VERSION "dbc-export 1 2026.26.6.5"

NS_ :

BS_:

BU_: APB APP APS DAS DPB EPAS3S EPASTS ESP GTW IBST IDB PARK RADC RCM RCM2 RCM3 RCU TPMS USM

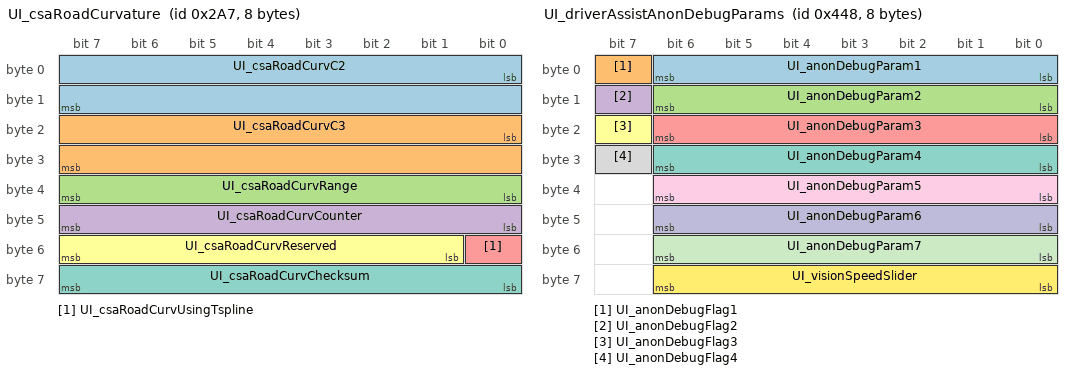
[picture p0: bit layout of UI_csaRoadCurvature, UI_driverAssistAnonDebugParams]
BO_ 679 UI_csaRoadCurvature: 8 GTW
 SG_ UI_csaRoadCurvC2 : 0|16@1- (1.0e-06,0) [-0.032768|0.032767] "1/m" Vector__XXX
 SG_ UI_csaRoadCurvC3 : 16|16@1- (4.0e-09,0) [-0.000131072|0.000131068] "1/m2" Vector__XXX
 SG_ UI_csaRoadCurvRange : 32|8@1+ (2,0) [0|510] "m" Vector__XXX
 SG_ UI_csaRoadCurvCounter : 40|8@1+ (1,0) [0|255] "" Vector__XXX
 SG_ UI_csaRoadCurvUsingTspline : 48|1@1+ (1,0) [0|1] "" Vector__XXX
 SG_ UI_csaRoadCurvReserved : 49|7@1+ (1,0) [0|127] "" Vector__XXX
 SG_ UI_csaRoadCurvChecksum : 56|8@1+ (1,0) [0|255] "" Vector__XXX

BO_ 1096 UI_driverAssistAnonDebugParams: 8 GTW
 SG_ UI_anonDebugParam1 : 0|7@1+ (1,0) [0|127] "" Vector__XXX
 SG_ UI_anonDebugFlag1 : 7|1@1+ (1,0) [0|1] "" Vector__XXX
 SG_ UI_anonDebugParam2 : 8|7@1+ (1,0) [0|127] "" Vector__XXX
 SG_ UI_anonDebugFlag2 : 15|1@1+ (1,0) [0|1] "" Vector__XXX
 SG_ UI_anonDebugParam3 : 16|7@1+ (1,0) [0|127] "" Vector__XXX
 SG_ UI_anonDebugFlag3 : 23|1@1+ (1,0) [0|1] "" Vector__XXX
 SG_ UI_anonDebugParam4 : 24|7@1+ (1,0) [0|127] "" Vector__XXX
 SG_ UI_anonDebugFlag4 : 31|1@1+ (1,0) [0|1] "" Vector__XXX
 SG_ UI_anonDebugParam5 : 32|7@1+ (1,0) [0|127] "" Vector__XXX
 SG_ UI_anonDebugParam6 : 40|7@1+ (1,0) [0|127] "" Vector__XXX
 SG_ UI_anonDebugParam7 : 48|7@1+ (1,0) [0|127] "" Vector__XXX
 SG_ UI_visionSpeedSlider : 56|7@1+ (1,0) [0|127] "" Vector__XXX

BO_ 1016 UI_driverAssistControl: 8 GTW
 SG_ UI_autopilotControlRequest : 0|1@1+ (1,0) [0|1] "" Vector__XXX
 SG_ UI_ulcStalkConfirm : 1|1@1+ (1,0) [0|1] "" Vector__XXX
 SG_ UI_summonHeartbeat : 2|2@1+ (1,0) [0|3] "" Vector__XXX
 SG_ UI_curvSpeedAdaptDisable : 4|1@1+ (1,0) [0|1] "" Vector__XXX
 SG_ UI_dasDeveloper : 5|1@1+ (1,0) [0|1] "" Vector__XXX
 SG_ UI_enableVinAssociation : 6|1@1+ (1,0) [0|1] "" Vector__XXX
 SG_ UI_lssLkaEnabled : 7|1@1+ (1,0) [0|1] "" Vector__XXX
 SG_ UI_lssLdwEnabled : 8|1@1+ (1,0) [0|1] "" Vector__XXX
 SG_ UI_coastToCoast : 9|1@1+ (1,0) [0|1] "" Vector__XXX
 SG_ UI_autoSummonEnable : 10|1@1+ (1,0) [0|1] "" Vector__XXX
 SG_ UI_exceptionListEnable : 11|1@1+ (1,0) [0|1] "" Vector__XXX
 SG_ UI_roadCheckDisable : 12|1@1+ (1,0) [0|1] "" Vector__XXX
 SG_ UI_driveOnMapsEnable : 13|1@1+ (1,0) [0|1] "" Vector__XXX
 SG_ UI_handsOnRequirementDisable : 14|1@1+ (1,0) [0|1] "" Vector__XXX
 SG_ UI_ulcOffHighway : 15|1@1+ (1,0) [0|1] "" Vector__XXX
 SG_ UI_fuseLanesDisable : 16|1@1+ (1,0) [0|1] "" Vector__XXX
 SG_ UI_fuseHPPDisable : 17|1@1+ (1,0) [0|1] "" Vector__XXX
 SG_ UI_fuseVehiclesDisable : 18|1@1+ (1,0) [0|1] "" Vector__XXX
 SG_ UI_enableClipParkedTelemetry : 19|1@1+ (1,0) [0|1] "" Vector__XXX
 SG_ UI_visionSpeedType : 20|2@1+ (1,0) [0|3] "" Vector__XXX
 SG_ UI_curvatureDatabaseOnly : 22|1@1+ (1,0) [0|1] "" Vector__XXX
 SG_ UI_lssElkEnabled : 23|1@1+ (1,0) [0|1] "" Vector__XXX
 SG_ UI_summonExitType : 24|2@1+ (1,0) [0|2] "" Vector__XXX
 SG_ UI_summonEntryType : 26|2@1+ (1,0) [0|2] "" Vector__XXX
 SG_ UI_selfParkRequest : 28|4@1+ (1,0) [0|14] "" Vector__XXX
 SG_ UI_summonReverseDist : 32|6@1+ (1,0) [0|62] "" Vector__XXX
 SG_ UI_undertakeAssistEnable : 38|1@1+ (1,0) [0|1] "" Vector__XXX
 SG_ UI_adaptiveSetSpeedEnable : 39|1@1+ (1,0) [0|1] "" Vector__XXX
 SG_ UI_drivingSide : 40|2@1+ (1,0) [0|3] "" Vector__XXX
 SG_ UI_enableClipTelemetry : 42|1@1+ (1,0) [0|1] "" Vector__XXX
 SG_ UI_enableTripTelemetry : 43|1@1+ (1,0) [0|1] "" Vector__XXX
 SG_ UI_enableRoadSegmentTelemetry : 44|1@1+ (1,0) [0|1] "" Vector__XXX
 SG_ UI_accFollowDistanceSetting : 45|3@1+ (1,0) [0|6] "" Vector__XXX
 SG_ UI_hasDriveOnNav : 48|1@1+ (1,0) [0|1] "" Vector__XXX
 SG_ UI_followNavRouteEnable : 49|1@1+ (1,0) [0|1] "" Vector__XXX
 SG_ UI_ulcSpeedConfig : 50|2@1+ (1,0) [0|3] "" Vector__XXX
 SG_ UI_ulcBlindSpotConfig : 52|2@1+ (1,0) [0|3] "" Vector__XXX
 SG_ UI_suppressExitPassingLane : 54|1@1+ (1,0) [0|1] "" Vector__XXX
 SG_ UI_enableClipStartStopTelemetry : 55|1@1+ (1,0) [0|1] "" Vector__XXX
 SG_ UI_alcOffHighwayEnable : 56|1@1+ (1,0) [0|1] "" Vector__XXX
 SG_ UI_validationLoop : 57|1@1+ (1,0) [0|1] "" Vector__XXX
 SG_ UI_smartSummonType : 58|2@1+ (1,0) [0|3] "" Vector__XXX
 SG_ UI_enableVisionOnlyStops : 60|1@1+ (1,0) [0|1] "" Vector__XXX
 SG_ UI_source3D : 61|2@1+ (1,0) [0|3] "" Vector__XXX
 SG_ UI_isaSpeedingChimeMuted : 63|1@1+ (1,0) [0|1] "" Vector__XXX

BO_ 568 UI_driverAssistMapData: 8 GTW
 SG_ UI_mapSpeedLimitDependency : 0|3@1+ (1,0) [0|6] "" Vector__XXX
 SG_ UI_roadClass : 3|3@1+ (1,0) [1|7] "" Vector__XXX
 SG_ UI_inSuperchargerGeofence : 6|1@1+ (1,0) [0|1] "" Vector__XXX
 SG_ UI_mapSpeedUnits : 7|1@1+ (1,0) [0|1] "" Vector__XXX
 SG_ UI_mapSpeedLimit : 8|5@1+ (1,0) [0|30] "" Vector__XXX
 SG_ UI_mapSpeedLimitType : 13|3@1+ (1,0) [0|6] "" Vector__XXX
 SG_ UI_countryCode : 16|10@1+ (1,0) [0|1022] "" Vector__XXX
 SG_ UI_streetCount : 26|2@1+ (1,0) [0|3] "" Vector__XXX
 SG_ UI_gpsRoadMatch : 28|1@1+ (1,0) [0|1] "" Vector__XXX
 SG_ UI_navRouteActive : 29|1@1+ (1,0) [0|1] "" Vector__XXX
 SG_ UI_parallelAutoparkEnabled : 30|1@1+ (1,0) [0|1] "" Vector__XXX
 SG_ UI_perpendicularAutoparkEnabled : 31|1@1+ (1,0) [0|1] "" Vector__XXX
 SG_ UI_nextBranchDist : 32|5@1+ (10,0) [0|300] "m" Vector__XXX
 SG_ UI_controlledAccess : 37|1@1+ (1,0) [0|1] "" Vector__XXX
 SG_ UI_nextBranchLeftOffRamp : 38|1@1+ (1,0) [0|1] "" Vector__XXX
 SG_ UI_nextBranchRightOffRamp : 39|1@1+ (1,0) [0|1] "" Vector__XXX
 SG_ UI_rejectLeftLane : 40|1@1+ (1,0) [0|1] "" Vector__XXX
 SG_ UI_rejectRightLane : 41|1@1+ (1,0) [0|1] "" Vector__XXX
 SG_ UI_rejectHPP : 42|1@1+ (1,0) [0|1] "" Vector__XXX
 SG_ UI_rejectNav : 43|1@1+ (1,0) [0|1] "" Vector__XXX
 SG_ UI_rejectLeftFreeSpace : 44|1@1+ (1,0) [0|1] "" Vector__XXX
 SG_ UI_rejectRightFreeSpace : 45|1@1+ (1,0) [0|1] "" Vector__XXX
 SG_ UI_rejectAutosteer : 46|1@1+ (1,0) [0|1] "" Vector__XXX
 SG_ UI_rejectHandsOn : 47|1@1+ (1,0) [0|1] "" Vector__XXX
 SG_ UI_acceptBottsDots : 48|1@1+ (1,0) [0|1] "" Vector__XXX
 SG_ UI_autosteerRestricted : 49|1@1+ (1,0) [0|1] "" Vector__XXX
 SG_ UI_pmmEnabled : 50|1@1+ (1,0) [0|1] "" Vector__XXX
 SG_ UI_scaEnabled : 51|1@1+ (1,0) [0|1] "" Vector__XXX
 SG_ UI_mapDataCounter : 52|4@1+ (1,0) [0|15] "" Vector__XXX
 SG_ UI_mapDataChecksum : 56|8@1+ (1,0) [0|255] "" Vector__XXX

BO_ 536 UI_driverAssistRoadSign: 8 GTW
 SG_ UI_roadSign M : 0|8@1+ (1,0) [0|254] "" Vector__XXX
 SG_ UI_splineLocConfidence : 40|7@1+ (1,0) [1|127] "1" Vector__XXX
 SG_ UI_splineID : 48|4@1+ (1,0) [0|15] "" Vector__XXX
 SG_ UI_roadSignCounter : 52|4@1+ (1,0) [0|15] "" Vector__XXX
 SG_ UI_roadSignChecksum : 56|8@1+ (1,0) [0|255] "" Vector__XXX
 SG_ UI_dummyData m0 : 8|1@1+ (1,0) [0|1] "" Vector__XXX
 SG_ UI_stopSignStopLineDist m1 : 8|10@1+ (0.25,-8) [-8|247.5] "m" Vector__XXX
 SG_ UI_stopSignStopLineConf m1 : 18|7@1+ (1,0) [1|127] "1" Vector__XXX
 SG_ UI_trafficLightStopLineDist m2 : 8|10@1+ (0.25,-8) [-8|247.5] "m" Vector__XXX
 SG_ UI_trafficLightStopLineConf m2 : 18|7@1+ (1,0) [1|127] "1" Vector__XXX
 SG_ UI_baseMapSpeedLimitMPS m3 : 8|8@1+ (0.25,0) [0|63.5] "m/s" Vector__XXX
 SG_ UI_bottomQrtlFleetSpeedMPS m3 : 16|8@1+ (0.25,0) [0|63.5] "m/s" Vector__XXX
 SG_ UI_topQrtlFleetSpeedMPS m3 : 24|8@1+ (0.25,0) [0|63.5] "m/s" Vector__XXX
 SG_ UI_meanFleetSplineSpeedMPS m4 : 8|8@1+ (0.25,0) [0|63.5] "m/s" Vector__XXX
 SG_ UI_medianFleetSpeedMPS m4 : 16|8@1+ (0.25,0) [0|63.5] "m/s" Vector__XXX
 SG_ UI_meanFleetSplineAccelMPS2 m4 : 24|8@1+ (0.05,-6.35) [-6.35|6.35] "m/s^2" Vector__XXX
 SG_ UI_rampType m4 : 32|3@1+ (1,0) [1|7] "" Vector__XXX
 SG_ UI_valhallaRamp m4 : 35|2@1+ (1,0) [1|3] "" Vector__XXX
 SG_ UI_overrideACMFleetSpeed m4 : 38|1@1+ (1,0) [0|1] "" Vector__XXX
 SG_ UI_currSplineIdFull m5 : 8|32@1+ (1,0) [1|4294967295] "1" Vector__XXX

BO_ 1971 UI_dynamicTriggersCampaignFired: 8 GTW
 SG_ UI_campaignFired : 0|64@1+ (1,0) [0|1.84467440737e+19] "" Vector__XXX

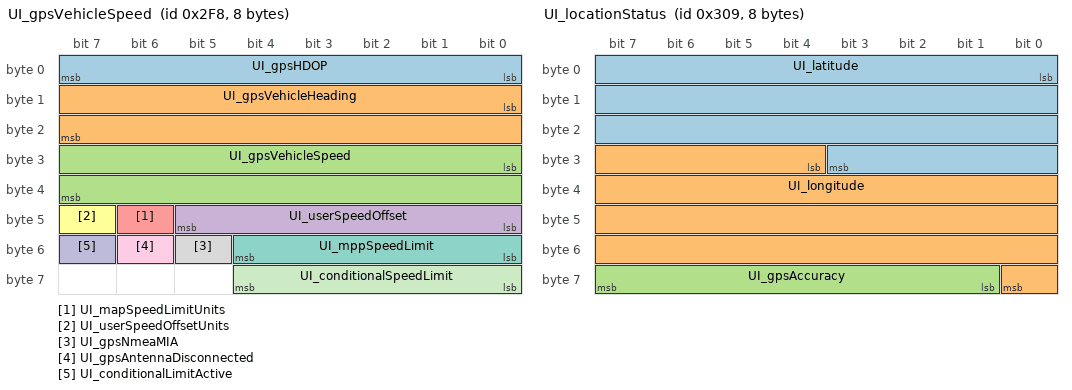
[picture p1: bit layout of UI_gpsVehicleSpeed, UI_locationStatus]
BO_ 760 UI_gpsVehicleSpeed: 8 GTW
 SG_ UI_gpsHDOP : 0|8@1+ (0.1,0) [0|25.5] "1" Vector__XXX
 SG_ UI_gpsVehicleHeading : 8|16@1+ (0.0078125,0) [0|511.9921875] "deg" Vector__XXX
 SG_ UI_gpsVehicleSpeed : 24|16@1+ (0.00390625,0) [0|255.99609375] "km/hr" Vector__XXX
 SG_ UI_userSpeedOffset : 40|6@1+ (1,-30) [-30|33] "kph/mph" Vector__XXX
 SG_ UI_mapSpeedLimitUnits : 46|1@1+ (1,0) [0|1] "" Vector__XXX
 SG_ UI_userSpeedOffsetUnits : 47|1@1+ (1,0) [0|1] "" Vector__XXX
 SG_ UI_mppSpeedLimit : 48|5@1+ (5,0) [0|155] "kph/mph" Vector__XXX
 SG_ UI_gpsNmeaMIA : 53|1@1+ (1,0) [0|1] "" Vector__XXX
 SG_ UI_gpsAntennaDisconnected : 54|1@1+ (1,0) [0|1] "" Vector__XXX
 SG_ UI_conditionalLimitActive : 55|1@1+ (1,0) [0|1] "" Vector__XXX
 SG_ UI_conditionalSpeedLimit : 56|5@1+ (5,0) [0|150] "kph/mph" Vector__XXX

BO_ 985 UI_locationOffset: 8 GTW
 SG_ UI_latitudeOffset : 0|28@1- (1.0e-06,0) [-134.217728|134.217727] "deg" Vector__XXX
 SG_ UI_longitudeOffset : 28|29@1- (1.0e-06,0) [-268.435456|268.435455] "deg" Vector__XXX

BO_ 777 UI_locationStatus: 8 GTW
 SG_ UI_latitude : 0|28@1- (1.0e-06,0) [-134.217728|134.217727] "deg" Vector__XXX
 SG_ UI_longitude : 28|29@1- (1.0e-06,0) [-268.435456|268.435455] "deg" Vector__XXX
 SG_ UI_gpsAccuracy : 57|7@1+ (0.2,0) [0|25.2] "m" Vector__XXX

BO_ 1011 UI_odo: 3 GTW
 SG_ UI_odometer : 0|24@1+ (0.1,0) [0|1677721.4] "km" Vector__XXX

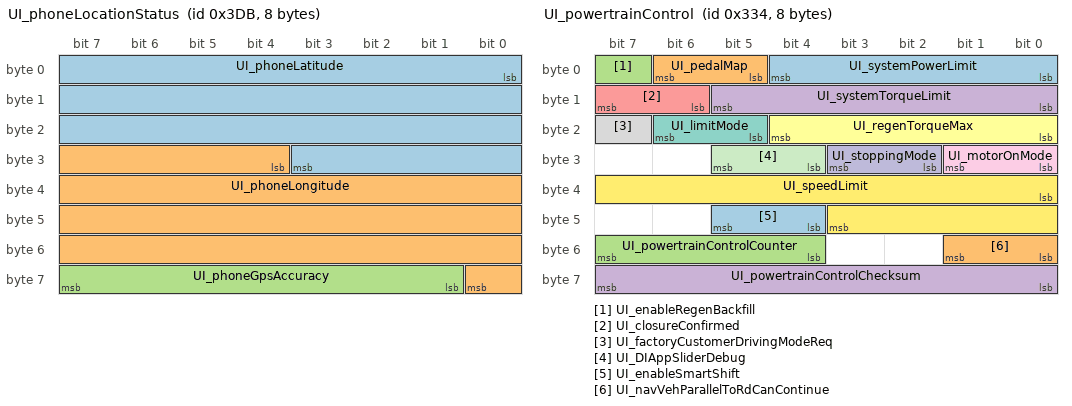
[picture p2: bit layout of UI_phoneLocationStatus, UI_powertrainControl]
BO_ 987 UI_phoneLocationStatus: 8 GTW
 SG_ UI_phoneLatitude : 0|28@1- (1.0e-06,0) [-134.217728|134.217727] "deg" Vector__XXX
 SG_ UI_phoneLongitude : 28|29@1- (1.0e-06,0) [-268.435456|268.435455] "deg" Vector__XXX
 SG_ UI_phoneGpsAccuracy : 57|7@1+ (0.5,0) [0|63] "m" Vector__XXX

BO_ 820 UI_powertrainControl: 8 GTW
 SG_ UI_systemPowerLimit : 0|5@1+ (20,20) [20|620] "kW" Vector__XXX
 SG_ UI_pedalMap : 5|2@1+ (1,0) [0|3] "" Vector__XXX
 SG_ UI_enableRegenBackfill : 7|1@1+ (1,0) [0|1] "" Vector__XXX
 SG_ UI_systemTorqueLimit : 8|6@1+ (150,1000) [1000|10300] "Nm" Vector__XXX
 SG_ UI_closureConfirmed : 14|2@1+ (1,0) [0|3] "" Vector__XXX
 SG_ UI_regenTorqueMax : 16|5@1+ (5,0) [0|100] "%" Vector__XXX
 SG_ UI_limitMode : 21|2@1+ (1,0) [0|3] "" Vector__XXX
 SG_ UI_factoryCustomerDrivingModeReq : 23|1@1+ (1,0) [0|1] "" Vector__XXX
 SG_ UI_motorOnMode : 24|2@1+ (1,0) [0|3] "" Vector__XXX
 SG_ UI_stoppingMode : 26|2@1+ (1,0) [0|3] "" Vector__XXX
 SG_ UI_DIAppSliderDebug : 28|2@1+ (1,0) [0|3] "" Vector__XXX
 SG_ UI_speedLimit : 32|12@1+ (0.1,0) [0|335] "kph" Vector__XXX
 SG_ UI_enableSmartShift : 44|2@1+ (1,0) [0|3] "" Vector__XXX
 SG_ UI_navVehParallelToRdCanContinue : 48|2@1+ (1,0) [1|3] "" Vector__XXX
 SG_ UI_powertrainControlCounter : 52|4@1+ (1,0) [0|15] "" Vector__XXX
 SG_ UI_powertrainControlChecksum : 56|8@1+ (1,0) [0|255] "" Vector__XXX

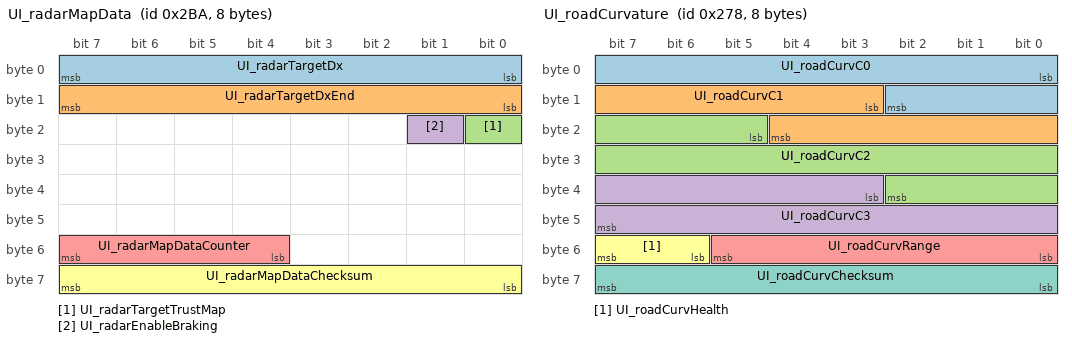
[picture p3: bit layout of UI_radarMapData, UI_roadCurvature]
BO_ 698 UI_radarMapData: 8 GTW
 SG_ UI_radarTargetDx : 0|8@1+ (1,-95) [-95|160] "m" Vector__XXX
 SG_ UI_radarTargetDxEnd : 8|8@1+ (1,0) [0|255] "m" Vector__XXX
 SG_ UI_radarTargetTrustMap : 16|1@1+ (1,0) [0|1] "" Vector__XXX
 SG_ UI_radarEnableBraking : 17|1@1+ (1,0) [0|1] "" Vector__XXX
 SG_ UI_radarMapDataCounter : 52|4@1+ (1,0) [0|15] "" Vector__XXX
 SG_ UI_radarMapDataChecksum : 56|8@1+ (1,0) [0|255] "" Vector__XXX

BO_ 632 UI_roadCurvature: 8 GTW
 SG_ UI_roadCurvC0 : 0|11@1- (0.02,0) [-20.48|20.46] "m" Vector__XXX
 SG_ UI_roadCurvC1 : 11|10@1- (0.00075,0) [-0.384|0.38325] "1" Vector__XXX
 SG_ UI_roadCurvC2 : 21|14@1- (7.5e-06,0) [-0.06144|0.0614325] "1/m" Vector__XXX
 SG_ UI_roadCurvC3 : 35|13@1- (3.0e-08,0) [-0.00012288|0.00012285] "1/m2" Vector__XXX
 SG_ UI_roadCurvRange : 48|6@1+ (4,0) [0|252] "m" Vector__XXX
 SG_ UI_roadCurvHealth : 54|2@1+ (1,0) [0|3] "" Vector__XXX
 SG_ UI_roadCurvChecksum : 56|8@1+ (1,0) [0|255] "" Vector__XXX

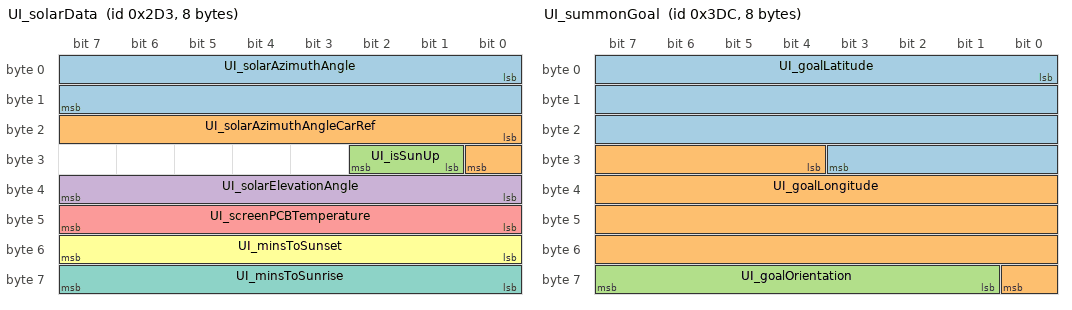
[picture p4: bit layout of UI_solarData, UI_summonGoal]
BO_ 723 UI_solarData: 8 GTW
 SG_ UI_solarAzimuthAngle : 0|16@1- (1,0) [-32768|32767] "degrees" Vector__XXX
 SG_ UI_solarAzimuthAngleCarRef : 16|9@1- (1,0) [-256|254] "degrees" Vector__XXX
 SG_ UI_isSunUp : 25|2@1+ (1,0) [0|2] "" Vector__XXX
 SG_ UI_solarElevationAngle : 32|8@1- (1,0) [-128|126] "degrees" Vector__XXX
 SG_ UI_screenPCBTemperature : 40|8@1- (0.5,40) [-20|100] "degC" Vector__XXX
 SG_ UI_minsToSunset : 48|8@1+ (10,0) [0|2550] "min" Vector__XXX
 SG_ UI_minsToSunrise : 56|8@1+ (10,0) [0|2550] "min" Vector__XXX

BO_ 851 UI_status: 8 GTW
 SG_ UI_touchActive : 0|1@1+ (1,0) [0|1] "" Vector__XXX
 SG_ UI_audioActive : 1|1@1+ (1,0) [0|1] "" Vector__XXX
 SG_ UI_bluetoothActive : 2|1@1+ (1,0) [0|1] "" Vector__XXX
 SG_ UI_cellActive : 3|1@1+ (1,0) [0|1] "" Vector__XXX
 SG_ UI_displayReady : 4|1@1+ (1,0) [0|1] "" Vector__XXX
 SG_ UI_displayOn : 5|1@1+ (1,0) [0|1] "" Vector__XXX
 SG_ UI_wifiActive : 6|1@1+ (1,0) [0|1] "" Vector__XXX
 SG_ UI_wifiConnected : 7|1@1+ (1,0) [0|1] "" Vector__XXX
 SG_ UI_systemActive : 8|1@1+ (1,0) [0|1] "" Vector__XXX
 SG_ UI_readyForDrive : 9|1@1+ (1,0) [0|1] "" Vector__XXX
 SG_ UI_cellConnected : 10|1@1+ (1,0) [0|1] "" Vector__XXX
 SG_ UI_vpnActive : 11|1@1+ (1,0) [0|1] "" Vector__XXX
 SG_ UI_autopilotTrial : 12|2@1+ (1,0) [0|3] "" Vector__XXX
 SG_ UI_factoryReset : 14|2@1+ (1,0) [1|3] "" Vector__XXX
 SG_ UI_gpsActive : 16|1@1+ (1,0) [0|1] "" Vector__XXX
 SG_ UI_screenshotActive : 17|1@1+ (1,0) [0|1] "" Vector__XXX
 SG_ UI_radioActive : 18|1@1+ (1,0) [0|1] "" Vector__XXX
 SG_ UI_cellNetworkTechnology : 19|4@1+ (1,0) [0|14] "" Vector__XXX
 SG_ UI_cellReceiverPower : 24|8@1+ (1,-128) [-128|127] "dB" Vector__XXX
 SG_ UI_falseTouchCounter : 32|8@1+ (1,0) [0|255] "1" Vector__XXX
 SG_ UI_developmentCar : 40|1@1+ (1,0) [0|1] "" Vector__XXX
 SG_ UI_cameraActive : 41|1@1+ (1,0) [0|1] "" Vector__XXX
 SG_ UI_cellSignalBars : 42|3@1+ (1,0) [0|6] "" Vector__XXX
 SG_ UI_trailerModeTelltale : 45|2@1+ (1,0) [0|3] "" Vector__XXX
 SG_ UI_pcbTemperature : 48|8@1- (1,40) [-20|100] "degC" Vector__XXX
 SG_ UI_cpuTemperature : 56|8@1- (1,40) [-20|100] "degC" Vector__XXX

BO_ 991 UI_status2: 8 GTW
 SG_ UI_mobileAppStepCount : 0|16@1+ (1,0) [0|65535] "" Vector__XXX
 SG_ UI_userRequestSnapshot : 16|1@1+ (1,0) [0|1] "" Vector__XXX
 SG_ UI_touchDetected : 17|1@1+ (1,0) [0|1] "" Vector__XXX
 SG_ UI_validDeviceForEUSummon : 18|1@1+ (1,0) [0|1] "" Vector__XXX
 SG_ UI_locatedAtHome : 19|1@1+ (1,0) [0|1] "" Vector__XXX
 SG_ UI_locatedAtWork : 20|1@1+ (1,0) [0|1] "" Vector__XXX
 SG_ UI_locatedAtFavorite : 21|1@1+ (1,0) [0|1] "" Vector__XXX
 SG_ UI_displayInDarkMode : 22|1@1+ (1,0) [0|1] "" Vector__XXX
 SG_ UI_userActivity : 23|1@1+ (1,0) [0|1] "" Vector__XXX
 SG_ UI_activeTouchPoints : 24|8@1+ (1,0) [0|255] "1" Vector__XXX
 SG_ UI_linkState : 32|2@1+ (1,0) [0|3] "" Vector__XXX
 SG_ UI_sentryModeState : 34|3@1+ (1,0) [0|7] "" Vector__XXX
 SG_ UI_autopilotSentryRequest : 37|1@1+ (1,0) [0|1] "" Vector__XXX
 SG_ UI_mobileAppConnected : 38|1@1+ (1,0) [0|1] "" Vector__XXX
 SG_ UI_phoneLeftInCabin : 39|1@1+ (1,0) [0|1] "" Vector__XXX
 SG_ UI_autoshiftDRState : 40|3@1+ (1,0) [0|7] "" Vector__XXX
 SG_ UI_wifiBtModuleType : 43|3@1+ (1,0) [0|7] "" Vector__XXX
 SG_ UI_sohHealthStatus : 46|2@1+ (1,0) [0|3] "" Vector__XXX
 SG_ UI_selfParkState : 48|8@1+ (1,0) [0|254] "" Vector__XXX
 SG_ UI_summonDeviceIndex : 56|2@1+ (1,0) [0|3] "" Vector__XXX
 SG_ UI_fullScreenMode : 58|1@1+ (1,0) [0|1] "" Vector__XXX
 SG_ UI_sentryModeCameraDetection : 59|1@1+ (1,0) [0|1] "" Vector__XXX
 SG_ UI_wakeOnIPActive : 60|1@1+ (1,0) [0|1] "" Vector__XXX
 SG_ UI_sapActive : 61|1@1+ (1,0) [0|1] "" Vector__XXX
 SG_ UI_sapClients : 62|1@1+ (1,0) [0|1] "" Vector__XXX
 SG_ UI_connectivityStandbyActive : 63|1@1+ (1,0) [0|1] "" Vector__XXX

BO_ 988 UI_summonGoal: 8 GTW
 SG_ UI_goalLatitude : 0|28@1- (1.0e-06,0) [-134.217728|134.217727] "deg" Vector__XXX
 SG_ UI_goalLongitude : 28|29@1- (1.0e-06,0) [-268.435456|268.435455] "deg" Vector__XXX
 SG_ UI_goalOrientation : 57|7@1+ (2.8125,0) [0|357.1875] "deg" Vector__XXX

BO_ 1064 UI_telemetryControl: 8 GTW
 SG_ UI_TCR_enable : 0|1@1+ (1,0) [0|1] "" Vector__XXX
 SG_ UI_TCR_moveStateStanding : 1|1@1+ (1,0) [0|1] "" Vector__XXX
 SG_ UI_TCR_moveStateStopped : 2|1@1+ (1,0) [0|1] "" Vector__XXX
 SG_ UI_TCR_moveStateMoving : 3|1@1+ (1,0) [0|1] "" Vector__XXX
 SG_ UI_TCR_moveStateIndeterm : 4|1@1+ (1,0) [0|1] "" Vector__XXX
 SG_ UI_TCR_classConstElem : 5|1@1+ (1,0) [0|1] "" Vector__XXX
 SG_ UI_TCR_classMovingPed : 6|1@1+ (1,0) [0|1] "" Vector__XXX
 SG_ UI_TCR_classMovingTwoWheel : 7|1@1+ (1,0) [0|1] "" Vector__XXX
 SG_ UI_TCR_classMovingFourWheel : 8|1@1+ (1,0) [0|1] "" Vector__XXX
 SG_ UI_TCR_classUnknown : 9|1@1+ (1,0) [0|1] "" Vector__XXX
 SG_ UI_TCR_downSampleFactor : 10|4@1+ (1,0) [0|15] "" Vector__XXX
 SG_ UI_TCR_wExist : 24|5@1+ (1,0) [0|31] "" Vector__XXX
 SG_ UI_TCR_vehSpeed : 32|8@1+ (1,0) [0|255] "" Vector__XXX
 SG_ UI_TCR_minRCS : 40|8@1+ (0.25,-14) [-14|49.75] "dB" Vector__XXX
 SG_ UI_TCR_maxDy : 48|5@1+ (0.5,0) [0|15.5] "m" Vector__XXX
 SG_ UI_TCR_maxObjects : 56|5@1+ (1,0) [0|31] "" Vector__XXX
 SG_ UI_TCR_maxRoadClass : 61|3@1+ (1,0) [0|7] "" Vector__XXX

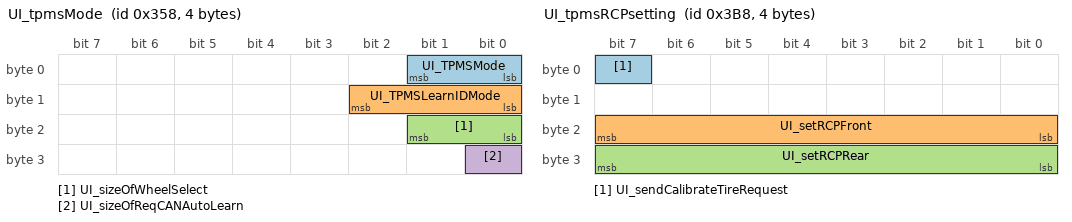
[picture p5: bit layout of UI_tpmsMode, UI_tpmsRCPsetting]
BO_ 856 UI_tpmsMode: 4 GTW
 SG_ UI_TPMSMode : 0|2@1+ (1,0) [0|3] "" Vector__XXX
 SG_ UI_TPMSLearnIDMode : 8|3@1+ (1,0) [0|7] "" Vector__XXX
 SG_ UI_sizeOfWheelSelect : 16|2@1+ (1,0) [0|3] "" Vector__XXX
 SG_ UI_sizeOfReqCANAutoLearn : 24|1@1+ (1,0) [0|1] "" Vector__XXX

BO_ 952 UI_tpmsRCPsetting: 4 GTW
 SG_ UI_sendCalibrateTireRequest : 7|1@1+ (1,0) [0|1] "" Vector__XXX
 SG_ UI_setRCPFront : 16|8@1+ (0.025,0) [0|6.375] "bar" Vector__XXX
 SG_ UI_setRCPRear : 24|8@1+ (0.025,0) [0|6.375] "bar" Vector__XXX

BO_ 852 UI_uiHealthStatus: 6 GTW
 SG_ UI_centerDisplayRunning : 0|1@1+ (1,0) [0|1] "" Vector__XXX
 SG_ UI_centerDisplaySM : 1|3@1+ (1,0) [0|7] "" Vector__XXX
 SG_ UI_centerDisplayPowerOn : 4|1@1+ (1,0) [0|1] "" Vector__XXX
 SG_ UI_centerDisplayCrtcOk : 5|1@1+ (1,0) [0|1] "" Vector__XXX
 SG_ UI_centerDisplayHardwareOk : 6|1@1+ (1,0) [0|1] "" Vector__XXX
 SG_ UI_centerDisplayWindowManagerOk : 7|1@1+ (1,0) [0|1] "" Vector__XXX
 SG_ UI_centerDisplayCompositorOk : 8|1@1+ (1,0) [0|1] "" Vector__XXX
 SG_ UI_apVisualizationOk : 9|1@1+ (1,0) [0|1] "" Vector__XXX
 SG_ UI_autonomyCenterDispStatus : 10|2@1+ (1,0) [1|3] "" Vector__XXX
 SG_ UI_autonomyRearDispStatus : 12|2@1+ (1,0) [1|3] "" Vector__XXX
 SG_ UI_autonomyConnectivityStatus : 14|2@1+ (1,0) [1|3] "" Vector__XXX
 SG_ UI_autonomyConnectivtyHWOk : 16|1@1+ (1,0) [0|1] "" Vector__XXX
 SG_ UI_autonomyQtCarStatus : 17|2@1+ (1,0) [1|3] "" Vector__XXX
 SG_ UI_autonomyQtCarRearStatus : 19|2@1+ (1,0) [1|3] "" Vector__XXX
 SG_ UI_autonomyDASServerStatus : 21|2@1+ (1,0) [1|3] "" Vector__XXX
 SG_ UI_rearDisplayRunning : 23|1@1+ (1,0) [0|1] "" Vector__XXX
 SG_ UI_rearDisplayPowerOn : 24|1@1+ (1,0) [0|1] "" Vector__XXX
 SG_ UI_rearDisplaySM : 25|3@1+ (1,0) [0|7] "" Vector__XXX
 SG_ UI_rearDisplayCrtcOk : 28|1@1+ (1,0) [0|1] "" Vector__XXX
 SG_ UI_rearDisplayHardwareOk : 29|1@1+ (1,0) [0|1] "" Vector__XXX
 SG_ UI_rearDisplayWindowManagerOk : 30|1@1+ (1,0) [0|1] "" Vector__XXX
 SG_ UI_rearDisplayCompositorOk : 31|1@1+ (1,0) [0|1] "" Vector__XXX

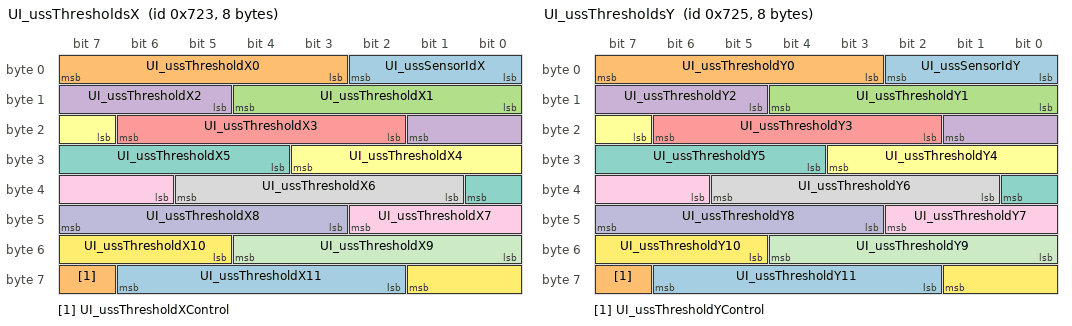
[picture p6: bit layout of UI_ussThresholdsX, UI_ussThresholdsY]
BO_ 1827 UI_ussThresholdsX: 8 GTW
 SG_ UI_ussSensorIdX : 0|3@1+ (1,0) [0|7] "" Vector__XXX
 SG_ UI_ussThresholdX0 : 3|5@1+ (1,0) [0|31] "" Vector__XXX
 SG_ UI_ussThresholdX1 : 8|5@1+ (1,0) [0|31] "" Vector__XXX
 SG_ UI_ussThresholdX2 : 13|5@1+ (1,0) [0|31] "" Vector__XXX
 SG_ UI_ussThresholdX3 : 18|5@1+ (1,0) [0|31] "" Vector__XXX
 SG_ UI_ussThresholdX4 : 23|5@1+ (1,0) [0|31] "" Vector__XXX
 SG_ UI_ussThresholdX5 : 28|5@1+ (1,0) [0|31] "" Vector__XXX
 SG_ UI_ussThresholdX6 : 33|5@1+ (1,0) [0|31] "" Vector__XXX
 SG_ UI_ussThresholdX7 : 38|5@1+ (1,0) [0|31] "" Vector__XXX
 SG_ UI_ussThresholdX8 : 43|5@1+ (1,0) [0|31] "" Vector__XXX
 SG_ UI_ussThresholdX9 : 48|5@1+ (1,0) [0|31] "" Vector__XXX
 SG_ UI_ussThresholdX10 : 53|5@1+ (1,0) [0|31] "" Vector__XXX
 SG_ UI_ussThresholdX11 : 58|5@1+ (1,0) [0|31] "" Vector__XXX
 SG_ UI_ussThresholdXControl : 63|1@1+ (1,0) [0|1] "" Vector__XXX

BO_ 1829 UI_ussThresholdsY: 8 GTW
 SG_ UI_ussSensorIdY : 0|3@1+ (1,0) [0|7] "" Vector__XXX
 SG_ UI_ussThresholdY0 : 3|5@1+ (1,0) [0|31] "" Vector__XXX
 SG_ UI_ussThresholdY1 : 8|5@1+ (1,0) [0|31] "" Vector__XXX
 SG_ UI_ussThresholdY2 : 13|5@1+ (1,0) [0|31] "" Vector__XXX
 SG_ UI_ussThresholdY3 : 18|5@1+ (1,0) [0|31] "" Vector__XXX
 SG_ UI_ussThresholdY4 : 23|5@1+ (1,0) [0|31] "" Vector__XXX
 SG_ UI_ussThresholdY5 : 28|5@1+ (1,0) [0|31] "" Vector__XXX
 SG_ UI_ussThresholdY6 : 33|5@1+ (1,0) [0|31] "" Vector__XXX
 SG_ UI_ussThresholdY7 : 38|5@1+ (1,0) [0|31] "" Vector__XXX
 SG_ UI_ussThresholdY8 : 43|5@1+ (1,0) [0|31] "" Vector__XXX
 SG_ UI_ussThresholdY9 : 48|5@1+ (1,0) [0|31] "" Vector__XXX
 SG_ UI_ussThresholdY10 : 53|5@1+ (1,0) [0|31] "" Vector__XXX
 SG_ UI_ussThresholdY11 : 58|5@1+ (1,0) [0|31] "" Vector__XXX
 SG_ UI_ussThresholdYControl : 63|1@1+ (1,0) [0|1] "" Vector__XXX

BO_ 947 UI_vehicleControl2: 8 GTW
 SG_ UI_gloveboxRequest : 0|1@1+ (1,0) [0|1] "" Vector__XXX
 SG_ UI_trunkRequest : 1|1@1+ (1,0) [0|1] "" Vector__XXX
 SG_ UI_UMCUpdateInhibit : 2|1@1+ (1,0) [0|1] "" Vector__XXX
 SG_ UI_WCUpdateInhibit : 3|1@1+ (1,0) [0|1] "" Vector__XXX
 SG_ UI_soundHornOnLock : 4|1@1+ (1,0) [0|1] "" Vector__XXX
 SG_ UI_locksPanelActive : 5|1@1+ (1,0) [0|1] "" Vector__XXX
 SG_ UI_PINToDriveEnabled : 6|1@1+ (1,0) [0|1] "" Vector__XXX
 SG_ UI_PINToDrivePassed : 7|1@1+ (1,0) [0|1] "" Vector__XXX
 SG_ UI_disableMirrorAutoDim : 8|1@1+ (1,0) [0|1] "" Vector__XXX
 SG_ UI_lightSwitch : 9|3@1+ (1,0) [0|7] "" Vector__XXX
 SG_ UI_readyToAddKey : 12|1@1+ (1,0) [0|1] "" Vector__XXX
 SG_ UI_alarmTriggerRequest : 13|1@1+ (1,0) [0|1] "" Vector__XXX
 SG_ UI_VCSECFeature1 : 14|1@1+ (1,0) [0|1] "" Vector__XXX
 SG_ UI_VCLEFTFeature1 : 15|1@1+ (1,0) [0|1] "" Vector__XXX
 SG_ UI_summonState : 16|2@1+ (1,0) [1|3] "" Vector__XXX
 SG_ UI_displayOnForUser : 18|1@1+ (1,0) [0|1] "" Vector__XXX
 SG_ UI_freeRollModeRequest : 19|1@1+ (1,0) [0|1] "" Vector__XXX
 SG_ UI_BLEPushNotificationRequest : 20|1@1+ (1,0) [0|1] "" Vector__XXX
 SG_ UI_pairKeyQRCodeDisplaying : 21|1@1+ (1,0) [0|1] "" Vector__XXX
 SG_ UI_keepAutopilotAwake : 22|1@1+ (1,0) [0|1] "" Vector__XXX
 SG_ UI_batteryPreconditioningRequest : 23|1@1+ (1,0) [0|1] "" Vector__XXX
 SG_ UI_coastDownMode : 24|1@1+ (1,0) [0|1] "" Vector__XXX
 SG_ UI_autopilotPowerStateRequest : 25|2@1+ (1,0) [0|3] "" Vector__XXX
 SG_ UI_shorted12VCellTestMode : 27|2@1+ (1,0) [0|3] "" Vector__XXX
 SG_ UI_autoRollWindowsOnLockEnable : 29|1@1+ (1,0) [0|1] "" Vector__XXX
 SG_ UI_virtualPitchSensorOverrideOKF : 30|1@1+ (1,0) [0|1] "" Vector__XXX
 SG_ UI_conditionalLoggingEnabledVCSE : 31|1@1+ (1,0) [0|1] "" Vector__XXX
 SG_ UI_WC3UpdateInhibit : 32|1@1+ (1,0) [0|1] "" Vector__XXX
 SG_ UI_steeringWheelHeatReq : 33|1@1+ (1,0) [0|1] "" Vector__XXX
 SG_ UI_disableHorn : 34|1@1+ (1,0) [0|1] "" Vector__XXX
 SG_ UI_frontLeftSeatFanReq : 37|2@1+ (1,0) [0|3] "" Vector__XXX
 SG_ UI_frontRightSeatAutoClimateReq : 39|1@1+ (1,0) [0|1] "" Vector__XXX
 SG_ UI_frontRightSeatFanReq : 40|2@1+ (1,0) [0|3] "" Vector__XXX
 SG_ UI_3RLeftSeatHeatReq : 44|2@1+ (1,0) [0|3] "" Vector__XXX
 SG_ UI_3RRightSeatHeatReq : 46|2@1+ (1,0) [0|3] "" Vector__XXX
 SG_ UI_sleepFeature1 : 51|1@1+ (1,0) [0|1] "" Vector__XXX
 SG_ UI_dcr12VThreshold : 52|4@1+ (1,0) [0|15] "" Vector__XXX
 SG_ UI_frontLeftSeatAutoClimateReq : 56|1@1+ (1,0) [0|1] "" Vector__XXX
 SG_ UI_wiperHeaterReq : 57|1@1+ (1,0) [0|1] "" Vector__XXX
 SG_ UI_tireSeason : 59|1@1+ (1,0) [0|1] "" Vector__XXX
 SG_ UI_saveTireConfigReq : 60|1@1+ (1,0) [0|1] "" Vector__XXX
 SG_ UI_silentAlarm : 61|1@1+ (1,0) [0|1] "" Vector__XXX
 SG_ UI_sleepFeature2 : 63|1@1+ (1,0) [0|1] "" Vector__XXX

BO_ 644 UI_vehicleModes: 8 GTW
 SG_ UI_factoryMode : 0|1@1+ (1,0) [0|1] "" Vector__XXX
 SG_ UI_transportMode : 1|1@1+ (1,0) [0|1] "" Vector__XXX
 SG_ UI_showroomMode : 2|1@1+ (1,0) [0|1] "" Vector__XXX
 SG_ UI_serviceMode : 3|1@1+ (1,0) [0|1] "" Vector__XXX
 SG_ UI_isDelivered : 4|1@1+ (1,0) [0|1] "" Vector__XXX
 SG_ UI_hasEverBeenDelivered : 5|1@1+ (1,0) [0|1] "" Vector__XXX
 SG_ UI_homelinkV2Command0 : 8|8@1+ (1,0) [0|255] "" Vector__XXX
 SG_ UI_homelinkV2Command1 : 16|8@1+ (1,0) [0|255] "" Vector__XXX
 SG_ UI_homelinkV2Command2 : 24|8@1+ (1,0) [0|255] "" Vector__XXX
 SG_ UI_carWashMode : 32|1@1+ (1,0) [0|1] "" Vector__XXX
 SG_ UI_valetMode : 33|1@1+ (1,0) [0|1] "" Vector__XXX
 SG_ UI_gameMode : 34|1@1+ (1,0) [0|1] "" Vector__XXX
 SG_ UI_diagnosticsAllowed : 35|1@1+ (1,0) [0|1] "" Vector__XXX
 SG_ UI_serviceModePlus : 36|1@1+ (1,0) [0|1] "" Vector__XXX
 SG_ UI_premiumAmpPowerOff : 37|1@1+ (1,0) [0|1] "" Vector__XXX
 SG_ UI_signedCmdHardLocked : 38|1@1+ (1,0) [0|1] "" Vector__XXX
 SG_ UI_signedCmdServiceMode : 39|1@1+ (1,0) [0|1] "" Vector__XXX
 SG_ UI_closureEasterEggStatus : 40|2@1+ (1,0) [0|3] "" Vector__XXX
 SG_ UI_lightShowType : 42|3@1+ (1,0) [0|7] "" Vector__XXX
 SG_ UI_sohTestRequest : 45|1@1+ (1,0) [0|1] "" Vector__XXX
 SG_ UI_upkeepMode : 46|1@1+ (1,0) [0|1] "" Vector__XXX
 SG_ UI_vehicleModesCounter : 52|4@1+ (1,0) [0|15] "" Vector__XXX
 SG_ UI_vehicleModesChecksum : 56|8@1+ (1,0) [0|255] "" Vector__XXX

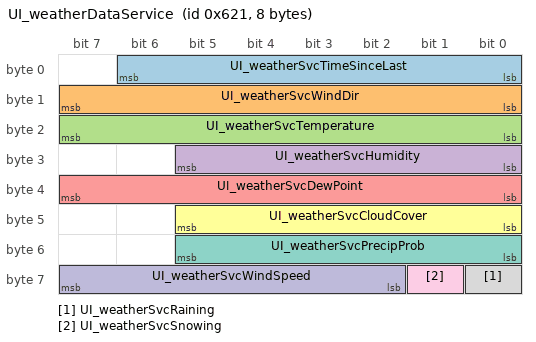
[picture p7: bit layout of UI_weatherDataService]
BO_ 1569 UI_weatherDataService: 8 GTW
 SG_ UI_weatherSvcTimeSinceLast : 0|7@1+ (1,0) [0|126] "minutes" Vector__XXX
 SG_ UI_weatherSvcWindDir : 8|8@1+ (1.5,0) [0|381] "deg" Vector__XXX
 SG_ UI_weatherSvcTemperature : 16|8@1+ (0.5,-40) [-40|87] "degC" Vector__XXX
 SG_ UI_weatherSvcHumidity : 24|6@1+ (1.62,0) [0|100.44] "%" Vector__XXX
 SG_ UI_weatherSvcDewPoint : 32|8@1+ (0.5,-60) [-60|67] "degC" Vector__XXX
 SG_ UI_weatherSvcCloudCover : 40|6@1+ (1.62,0) [0|100.44] "%" Vector__XXX
 SG_ UI_weatherSvcPrecipProb : 48|6@1+ (1.62,0) [0|100.44] "%" Vector__XXX
 SG_ UI_weatherSvcRaining : 56|1@1+ (1,0) [0|1] "" Vector__XXX
 SG_ UI_weatherSvcSnowing : 57|1@1+ (1,0) [0|1] "" Vector__XXX
 SG_ UI_weatherSvcWindSpeed : 58|6@1+ (2,0) [0|124] "kph" Vector__XXX

BO_TX_BU_ 679 : GTW;
BO_TX_BU_ 1096 : GTW;
BO_TX_BU_ 1016 : GTW;
BO_TX_BU_ 568 : GTW;
BO_TX_BU_ 536 : GTW;
BO_TX_BU_ 1971 : GTW;
BO_TX_BU_ 760 : GTW;
BO_TX_BU_ 985 : GTW;
BO_TX_BU_ 777 : GTW;
BO_TX_BU_ 1011 : GTW;
BO_TX_BU_ 987 : GTW;
BO_TX_BU_ 820 : GTW;
BO_TX_BU_ 698 : GTW;
BO_TX_BU_ 632 : GTW;
BO_TX_BU_ 723 : GTW;
BO_TX_BU_ 851 : GTW;
BO_TX_BU_ 991 : GTW;
BO_TX_BU_ 988 : GTW;
BO_TX_BU_ 1064 : GTW;
BO_TX_BU_ 856 : GTW;
BO_TX_BU_ 952 : GTW;
BO_TX_BU_ 852 : GTW;
BO_TX_BU_ 1827 : GTW;
BO_TX_BU_ 1829 : GTW;
BO_TX_BU_ 947 : GTW;
BO_TX_BU_ 644 : GTW;
BO_TX_BU_ 1569 : GTW;
CM_ BO_ 679 "Touchscreen user interface computer message: csa road curvature; forwarded onto this bus by the gateway; frame length from the layout, not yet observed on a vehicle bus";
CM_ SG_ 679 UI_csaRoadCurvC2 "Touchscreen user interface computer: csa road curv C2";
CM_ SG_ 679 UI_csaRoadCurvC3 "Touchscreen user interface computer: csa road curv C3";
CM_ SG_ 679 UI_csaRoadCurvRange "Touchscreen user interface computer: csa road curv range";
CM_ SG_ 679 UI_csaRoadCurvCounter "Touchscreen user interface computer: csa road curv counter";
CM_ SG_ 679 UI_csaRoadCurvUsingTspline "Touchscreen user interface computer: csa road curv using tspline";
CM_ SG_ 679 UI_csaRoadCurvReserved "Touchscreen user interface computer: csa road curv reserved";
CM_ SG_ 679 UI_csaRoadCurvChecksum "Touchscreen user interface computer: csa road curv checksum";
CM_ BO_ 1096 "Touchscreen user interface computer message: driver assist anon debug params; forwarded onto this bus by the gateway; frame length from the layout, not yet observed on a vehicle bus";
CM_ SG_ 1096 UI_anonDebugParam1 "Touchscreen user interface computer: anon debug param1";
CM_ SG_ 1096 UI_anonDebugFlag1 "Touchscreen user interface computer: anon debug flag1";
CM_ SG_ 1096 UI_anonDebugParam2 "Touchscreen user interface computer: anon debug param2";
CM_ SG_ 1096 UI_anonDebugFlag2 "Touchscreen user interface computer: anon debug flag2";
CM_ SG_ 1096 UI_anonDebugParam3 "Touchscreen user interface computer: anon debug param3";
CM_ SG_ 1096 UI_anonDebugFlag3 "Touchscreen user interface computer: anon debug flag3";
CM_ SG_ 1096 UI_anonDebugParam4 "Touchscreen user interface computer: anon debug param4";
CM_ SG_ 1096 UI_anonDebugFlag4 "Touchscreen user interface computer: anon debug flag4";
CM_ SG_ 1096 UI_anonDebugParam5 "Touchscreen user interface computer: anon debug param5";
CM_ SG_ 1096 UI_anonDebugParam6 "Touchscreen user interface computer: anon debug param6";
CM_ SG_ 1096 UI_anonDebugParam7 "Touchscreen user interface computer: anon debug param7";
CM_ SG_ 1096 UI_visionSpeedSlider "Touchscreen user interface computer: vision speed slider";
CM_ BO_ 1016 "Touchscreen user interface computer message: driver assist control; forwarded onto this bus by the gateway; frame length from the layout, not yet observed on a vehicle bus";
CM_ SG_ 1016 UI_autopilotControlRequest "Touchscreen user interface computer: autopilot control request";
CM_ SG_ 1016 UI_ulcStalkConfirm "Drive on autopilot stalk confirmation mode (set by feature config).";
CM_ SG_ 1016 UI_summonHeartbeat "Touchscreen user interface computer: summon heartbeat";
CM_ SG_ 1016 UI_curvSpeedAdaptDisable "Touchscreen user interface computer: curv speed adapt disable";
CM_ SG_ 1016 UI_dasDeveloper "Touchscreen user interface computer: das developer";
CM_ SG_ 1016 UI_enableVinAssociation "Touchscreen user interface computer: enable vin association";
CM_ SG_ 1016 UI_lssLkaEnabled "User setting for lane keep assist";
CM_ SG_ 1016 UI_lssLdwEnabled "User setting for lane departure warning";
CM_ SG_ 1016 UI_coastToCoast "Touchscreen user interface computer: coast to coast";
CM_ SG_ 1016 UI_autoSummonEnable "Touchscreen user interface computer: auto summon enable";
CM_ SG_ 1016 UI_exceptionListEnable "Touchscreen user interface computer: exception list enable";
CM_ SG_ 1016 UI_roadCheckDisable "Touchscreen user interface computer: road check disable";
CM_ SG_ 1016 UI_driveOnMapsEnable "Drive on Autopilot enabled";
CM_ SG_ 1016 UI_handsOnRequirementDisable "Touchscreen user interface computer: hands on requirement disable";
CM_ SG_ 1016 UI_ulcOffHighway "Touchscreen user interface computer: ulc off highway";
CM_ SG_ 1016 UI_fuseLanesDisable "Touchscreen user interface computer: fuse lanes disable";
CM_ SG_ 1016 UI_fuseHPPDisable "Touchscreen user interface computer: fuse HPP disable";
CM_ SG_ 1016 UI_fuseVehiclesDisable "Touchscreen user interface computer: fuse vehicles disable";
CM_ SG_ 1016 UI_enableClipParkedTelemetry "Touchscreen user interface computer: enable clip parked telemetry";
CM_ SG_ 1016 UI_visionSpeedType "Touchscreen user interface computer: vision speed type";
CM_ SG_ 1016 UI_curvatureDatabaseOnly "Touchscreen user interface computer: curvature database only";
CM_ SG_ 1016 UI_lssElkEnabled "User setting for emergency lane keep";
CM_ SG_ 1016 UI_summonExitType "Touchscreen user interface computer: summon exit type; raw 3 = signal not available (SNA)";
CM_ SG_ 1016 UI_summonEntryType "Touchscreen user interface computer: summon entry type; raw 3 = signal not available (SNA)";
CM_ SG_ 1016 UI_selfParkRequest "Self park request; raw 15 = signal not available (SNA)";
CM_ SG_ 1016 UI_summonReverseDist "Touchscreen user interface computer: summon reverse dist; raw 63 = signal not available (SNA)";
CM_ SG_ 1016 UI_undertakeAssistEnable "Touchscreen user interface computer: undertake assist enable";
CM_ SG_ 1016 UI_adaptiveSetSpeedEnable "Touchscreen user interface computer: adaptive set speed enable";
CM_ SG_ 1016 UI_drivingSide "Touchscreen user interface computer: driving side";
CM_ SG_ 1016 UI_enableClipTelemetry "Touchscreen user interface computer: enable clip telemetry";
CM_ SG_ 1016 UI_enableTripTelemetry "Touchscreen user interface computer: enable trip telemetry";
CM_ SG_ 1016 UI_enableRoadSegmentTelemetry "Touchscreen user interface computer: enable road segment telemetry";
CM_ SG_ 1016 UI_accFollowDistanceSetting "Touchscreen user interface computer: acc follow distance setting; raw 7 = signal not available (SNA)";
CM_ SG_ 1016 UI_hasDriveOnNav "Touchscreen user interface computer: has drive on nav";
CM_ SG_ 1016 UI_followNavRouteEnable "Following route with Drive on Autopilot";
CM_ SG_ 1016 UI_ulcSpeedConfig "Drive on autopilot speed base lane changes mode.";
CM_ SG_ 1016 UI_ulcBlindSpotConfig "Touchscreen user interface computer: ulc blind spot config";
CM_ SG_ 1016 UI_suppressExitPassingLane "Navigate on Autopilot will not suggest lane changes out of the passing lane";
CM_ SG_ 1016 UI_enableClipStartStopTelemetry "Touchscreen user interface computer: enable clip start stop telemetry";
CM_ SG_ 1016 UI_alcOffHighwayEnable "Touchscreen user interface computer: alc off highway enable";
CM_ SG_ 1016 UI_validationLoop "Touchscreen user interface computer: validation loop";
CM_ SG_ 1016 UI_smartSummonType "Type of smart summon session (Find Me, Pin Drop, Smart Autopark)";
CM_ SG_ 1016 UI_enableVisionOnlyStops "Touchscreen user interface computer: enable vision only stops";
CM_ SG_ 1016 UI_source3D "Touchscreen user interface computer: source3 d";
CM_ SG_ 1016 UI_isaSpeedingChimeMuted "Reports the user input of Intelligent Speed Assist (ISA) speed chime alert option.";
CM_ BO_ 568 "Touchscreen user interface computer message: driver assist map data; forwarded onto this bus by the gateway; frame length from the layout, not yet observed on a vehicle bus";
CM_ SG_ 568 UI_mapSpeedLimitDependency "Touchscreen user interface computer: map speed limit dependency; raw 7 = signal not available (SNA)";
CM_ SG_ 568 UI_roadClass "Autopilot map road class; raw 0 = signal not available (SNA)";
CM_ SG_ 568 UI_inSuperchargerGeofence "Touchscreen user interface computer: in supercharger geofence";
CM_ SG_ 568 UI_mapSpeedUnits "Touchscreen user interface computer: map speed units";
CM_ SG_ 568 UI_mapSpeedLimit "Touchscreen user interface computer: map speed limit; raw 31 = signal not available (SNA)";
CM_ SG_ 568 UI_mapSpeedLimitType "Touchscreen user interface computer: map speed limit type; raw 7 = signal not available (SNA)";
CM_ SG_ 568 UI_countryCode "Touchscreen user interface computer: country code; raw 1023 = signal not available (SNA)";
CM_ SG_ 568 UI_streetCount "Touchscreen user interface computer: street count";
CM_ SG_ 568 UI_gpsRoadMatch "Touchscreen user interface computer: gps road match";
CM_ SG_ 568 UI_navRouteActive "Navigation route is active";
CM_ SG_ 568 UI_parallelAutoparkEnabled "Autopilot map parallel park enabled.";
CM_ SG_ 568 UI_perpendicularAutoparkEnabled "Autopilot map perpendicular park enabled.";
CM_ SG_ 568 UI_nextBranchDist "Touchscreen user interface computer: next branch dist; raw 31 = signal not available (SNA)";
CM_ SG_ 568 UI_controlledAccess "DAS map controlled access segment.";
CM_ SG_ 568 UI_nextBranchLeftOffRamp "Touchscreen user interface computer: next branch left off ramp";
CM_ SG_ 568 UI_nextBranchRightOffRamp "Touchscreen user interface computer: next branch right off ramp";
CM_ SG_ 568 UI_rejectLeftLane "Touchscreen user interface computer: reject left lane";
CM_ SG_ 568 UI_rejectRightLane "Touchscreen user interface computer: reject right lane";
CM_ SG_ 568 UI_rejectHPP "Touchscreen user interface computer: reject HPP";
CM_ SG_ 568 UI_rejectNav "Touchscreen user interface computer: reject nav";
CM_ SG_ 568 UI_rejectLeftFreeSpace "Touchscreen user interface computer: reject left free space";
CM_ SG_ 568 UI_rejectRightFreeSpace "Touchscreen user interface computer: reject right free space";
CM_ SG_ 568 UI_rejectAutosteer "Touchscreen user interface computer: reject autosteer";
CM_ SG_ 568 UI_rejectHandsOn "Touchscreen user interface computer: reject hands on";
CM_ SG_ 568 UI_acceptBottsDots "Touchscreen user interface computer: accept botts dots";
CM_ SG_ 568 UI_autosteerRestricted "Autopilot map is autostreer restricted.";
CM_ SG_ 568 UI_pmmEnabled "Touchscreen user interface computer: pmm enabled";
CM_ SG_ 568 UI_scaEnabled "Touchscreen user interface computer: sca enabled";
CM_ SG_ 568 UI_mapDataCounter "Touchscreen user interface computer: map data counter";
CM_ SG_ 568 UI_mapDataChecksum "Touchscreen user interface computer: map data checksum";
CM_ BO_ 536 "Touchscreen user interface computer message: driver assist road sign; forwarded onto this bus by the gateway; frame length from the layout, not yet observed on a vehicle bus";
CM_ SG_ 536 UI_roadSign "Touchscreen user interface computer: road sign; raw 255 = signal not available (SNA)";
CM_ SG_ 536 UI_splineLocConfidence "Touchscreen user interface computer: spline loc confidence; raw 0 = signal not available (SNA)";
CM_ SG_ 536 UI_splineID "Touchscreen user interface computer: spline ID";
CM_ SG_ 536 UI_roadSignCounter "Touchscreen user interface computer: road sign counter";
CM_ SG_ 536 UI_roadSignChecksum "Touchscreen user interface computer: road sign checksum";
CM_ SG_ 536 UI_dummyData "Touchscreen user interface computer: dummy data";
CM_ SG_ 536 UI_stopSignStopLineDist "Touchscreen user interface computer: stop sign stop line dist; raw 1023 = signal not available (SNA)";
CM_ SG_ 536 UI_stopSignStopLineConf "Touchscreen user interface computer: stop sign stop line conf; raw 0 = signal not available (SNA)";
CM_ SG_ 536 UI_trafficLightStopLineDist "Touchscreen user interface computer: traffic light stop line dist; raw 1023 = signal not available (SNA)";
CM_ SG_ 536 UI_trafficLightStopLineConf "Touchscreen user interface computer: traffic light stop line conf; raw 0 = signal not available (SNA)";
CM_ SG_ 536 UI_baseMapSpeedLimitMPS "Touchscreen user interface computer: base map speed limit MPS; raw 255 = signal not available (SNA)";
CM_ SG_ 536 UI_bottomQrtlFleetSpeedMPS "Touchscreen user interface computer: bottom qrtl fleet speed MPS; raw 255 = signal not available (SNA)";
CM_ SG_ 536 UI_topQrtlFleetSpeedMPS "Touchscreen user interface computer: top qrtl fleet speed MPS; raw 255 = signal not available (SNA)";
CM_ SG_ 536 UI_meanFleetSplineSpeedMPS "Touchscreen user interface computer: mean fleet spline speed MPS; raw 255 = signal not available (SNA)";
CM_ SG_ 536 UI_medianFleetSpeedMPS "Touchscreen user interface computer: median fleet speed MPS; raw 255 = signal not available (SNA)";
CM_ SG_ 536 UI_meanFleetSplineAccelMPS2 "Touchscreen user interface computer: mean fleet spline accel MPS2; raw 255 = signal not available (SNA)";
CM_ SG_ 536 UI_rampType "Touchscreen user interface computer: ramp type; raw 0 = signal not available (SNA)";
CM_ SG_ 536 UI_valhallaRamp "Touchscreen user interface computer: valhalla ramp; raw 0 = signal not available (SNA)";
CM_ SG_ 536 UI_overrideACMFleetSpeed "Touchscreen user interface computer: override ACM fleet speed";
CM_ SG_ 536 UI_currSplineIdFull "Touchscreen user interface computer: curr spline id full; raw 0 = signal not available (SNA)";
CM_ BO_ 1971 "Touchscreen user interface computer message: dynamic triggers campaign fired; forwarded onto this bus by the gateway; frame length from the layout, not yet observed on a vehicle bus";
CM_ SG_ 1971 UI_campaignFired "Touchscreen user interface computer: campaign fired";
CM_ BO_ 760 "Touchscreen user interface computer message: gps vehicle speed; forwarded onto this bus by the gateway; frame length from the layout, not yet observed on a vehicle bus";
CM_ SG_ 760 UI_gpsHDOP "Touchscreen user interface computer: gps HDOP";
CM_ SG_ 760 UI_gpsVehicleHeading "Touchscreen user interface computer: gps vehicle heading";
CM_ SG_ 760 UI_gpsVehicleSpeed "Touchscreen user interface computer: gps vehicle speed";
CM_ SG_ 760 UI_userSpeedOffset "Touchscreen user interface computer: user speed offset";
CM_ SG_ 760 UI_mapSpeedLimitUnits "Autopilot map speed limit units.";
CM_ SG_ 760 UI_userSpeedOffsetUnits "Touchscreen user interface computer: user speed offset units";
CM_ SG_ 760 UI_mppSpeedLimit "Autopilot map speed limit";
CM_ SG_ 760 UI_gpsNmeaMIA "GPS NMEA data MIA";
CM_ SG_ 760 UI_gpsAntennaDisconnected "GPS antenna state";
CM_ SG_ 760 UI_conditionalLimitActive "Conditional speed limit condition is currently active";
CM_ SG_ 760 UI_conditionalSpeedLimit "Conditional speed limit value; raw 31 = signal not available (SNA)";
CM_ BO_ 985 "Touchscreen user interface computer message: location offset; forwarded onto this bus by the gateway; frame length from the layout, not yet observed on a vehicle bus";
CM_ SG_ 985 UI_latitudeOffset "Touchscreen user interface computer: latitude offset";
CM_ SG_ 985 UI_longitudeOffset "Touchscreen user interface computer: longitude offset";
CM_ BO_ 777 "Touchscreen user interface computer message: location status; forwarded onto this bus by the gateway; frame length from the layout, not yet observed on a vehicle bus";
CM_ SG_ 777 UI_latitude "Touchscreen user interface computer: latitude";
CM_ SG_ 777 UI_longitude "Touchscreen user interface computer: longitude";
CM_ SG_ 777 UI_gpsAccuracy "Touchscreen user interface computer: gps accuracy; raw 127 = signal not available (SNA)";
CM_ BO_ 1011 "Touchscreen user interface computer message: odo; forwarded onto this bus by the gateway; frame length from the layout, not yet observed on a vehicle bus";
CM_ SG_ 1011 UI_odometer "Odometer; raw 16777215 = signal not available (SNA)";
CM_ BO_ 987 "Touchscreen user interface computer message: phone location status; forwarded onto this bus by the gateway; frame length from the layout, not yet observed on a vehicle bus";
CM_ SG_ 987 UI_phoneLatitude "Touchscreen user interface computer: phone latitude";
CM_ SG_ 987 UI_phoneLongitude "Touchscreen user interface computer: phone longitude";
CM_ SG_ 987 UI_phoneGpsAccuracy "Touchscreen user interface computer: phone gps accuracy; raw 127 = signal not available (SNA)";
CM_ BO_ 820 "Touchscreen user interface computer message: powertrain control; forwarded onto this bus by the gateway; frame length from the layout, not yet observed on a vehicle bus";
CM_ SG_ 820 UI_systemPowerLimit "Touchscreen user interface computer: system power limit; raw 31 = signal not available (SNA)";
CM_ SG_ 820 UI_pedalMap "Switch between various platform specific pedal maps";
CM_ SG_ 820 UI_enableRegenBackfill "Indicates if regenerative braking backfill has been enabled by the driver";
CM_ SG_ 820 UI_systemTorqueLimit "Touchscreen user interface computer: system torque limit; raw 63 = signal not available (SNA)";
CM_ SG_ 820 UI_closureConfirmed "Touchscreen user interface computer: closure confirmed";
CM_ SG_ 820 UI_regenTorqueMax "Maximum regen torque from UI - reports different value when in track mode";
CM_ SG_ 820 UI_limitMode "Commands limited drive inverter capabilities based on special vehicle modes";
CM_ SG_ 820 UI_factoryCustomerDrivingModeReq "Touchscreen user interface computer: factory customer driving mode request";
CM_ SG_ 820 UI_motorOnMode "Request from the UI to selectively enable or disable a drive unit (dev-only)";
CM_ SG_ 820 UI_stoppingMode "Low-speed behavior when no pedal is pressed (stopping/rolling/creeping)";
CM_ SG_ 820 UI_DIAppSliderDebug "Touchscreen user interface computer: DI app slider debug";
CM_ SG_ 820 UI_speedLimit "Maximum allowed speed enforced at vehicle level; raw 511 = signal not available (SNA)";
CM_ SG_ 820 UI_enableSmartShift "Stalkless convenience feature that allows unparking with only a firm press of brake pedal";
CM_ SG_ 820 UI_navVehParallelToRdCanContinue "Whether the vehicle is parallel parked on a public road; raw 0 = signal not available (SNA)";
CM_ SG_ 820 UI_powertrainControlCounter "Touchscreen user interface computer: powertrain control counter";
CM_ SG_ 820 UI_powertrainControlChecksum "Touchscreen user interface computer: powertrain control checksum";
CM_ BO_ 698 "Touchscreen user interface computer message: radar map data; forwarded onto this bus by the gateway; frame length from the layout, not yet observed on a vehicle bus";
CM_ SG_ 698 UI_radarTargetDx "Touchscreen user interface computer: radar target dx";
CM_ SG_ 698 UI_radarTargetDxEnd "Touchscreen user interface computer: radar target dx end";
CM_ SG_ 698 UI_radarTargetTrustMap "Touchscreen user interface computer: radar target trust map";
CM_ SG_ 698 UI_radarEnableBraking "Touchscreen user interface computer: radar enable braking";
CM_ SG_ 698 UI_radarMapDataCounter "Touchscreen user interface computer: radar map data counter";
CM_ SG_ 698 UI_radarMapDataChecksum "Touchscreen user interface computer: radar map data checksum";
CM_ BO_ 632 "Touchscreen user interface computer message: road curvature; forwarded onto this bus by the gateway; frame length from the layout, not yet observed on a vehicle bus";
CM_ SG_ 632 UI_roadCurvC0 "Touchscreen user interface computer: road curv C0";
CM_ SG_ 632 UI_roadCurvC1 "Touchscreen user interface computer: road curv C1";
CM_ SG_ 632 UI_roadCurvC2 "Touchscreen user interface computer: road curv C2";
CM_ SG_ 632 UI_roadCurvC3 "Touchscreen user interface computer: road curv C3";
CM_ SG_ 632 UI_roadCurvRange "Touchscreen user interface computer: road curv range";
CM_ SG_ 632 UI_roadCurvHealth "Touchscreen user interface computer: road curv health";
CM_ SG_ 632 UI_roadCurvChecksum "Touchscreen user interface computer: road curv checksum";
CM_ BO_ 723 "Touchscreen user interface computer message: solar data; forwarded onto this bus by the gateway; frame length from the layout, not yet observed on a vehicle bus";
CM_ SG_ 723 UI_solarAzimuthAngle "Touchscreen user interface computer: solar azimuth angle; raw 32768 = signal not available (SNA)";
CM_ SG_ 723 UI_solarAzimuthAngleCarRef "Touchscreen user interface computer: solar azimuth angle car ref; raw 255 = signal not available (SNA)";
CM_ SG_ 723 UI_isSunUp "is sun up; raw 3 = signal not available (SNA)";
CM_ SG_ 723 UI_solarElevationAngle "Solar Elevation Angle; raw 127 = signal not available (SNA)";
CM_ SG_ 723 UI_screenPCBTemperature "Temperature of display PCB";
CM_ SG_ 723 UI_minsToSunset "time until to sunset";
CM_ SG_ 723 UI_minsToSunrise "time until to sunrise";
CM_ BO_ 851 "Touchscreen user interface computer message: status; forwarded onto this bus by the gateway; frame length from the layout, not yet observed on a vehicle bus";
CM_ SG_ 851 UI_touchActive "No touchscreen errors";
CM_ SG_ 851 UI_audioActive "Audio system is ready.";
CM_ SG_ 851 UI_bluetoothActive "Touchscreen user interface computer: bluetooth active";
CM_ SG_ 851 UI_cellActive "Cell is powered";
CM_ SG_ 851 UI_displayReady "UI is ready (GUI_allReady) and display is ok (GUI_displayHardwareOK)";
CM_ SG_ 851 UI_displayOn "UI display on/off status";
CM_ SG_ 851 UI_wifiActive "WiFi active.";
CM_ SG_ 851 UI_wifiConnected "WiFi Connected.";
CM_ SG_ 851 UI_systemActive "Touchscreen user interface computer: system active";
CM_ SG_ 851 UI_readyForDrive "Ready for drive (UI ready or self park request)";
CM_ SG_ 851 UI_cellConnected "Detects if the cell is connected to a network.";
CM_ SG_ 851 UI_vpnActive "VPN connected.";
CM_ SG_ 851 UI_autopilotTrial "Touchscreen user interface computer: autopilot trial";
CM_ SG_ 851 UI_factoryReset "UI request for factory reset; raw 0 = signal not available (SNA)";
CM_ SG_ 851 UI_gpsActive "GPS has valid fix";
CM_ SG_ 851 UI_screenshotActive "Touchscreen user interface computer: screenshot active";
CM_ SG_ 851 UI_radioActive "Touchscreen user interface computer: radio active";
CM_ SG_ 851 UI_cellNetworkTechnology "Describes the type of cellular network to which the car computer is connected: GPRS_2G(114Kbps) < EGDE_2G(368Kbps) < 3G(3Mbps) < HSDPA_3G(14Mbps) < HSPAplus_4Gg(168Mbps) < 4G_LTE(299Mbps); raw 15 = signal not available (SNA)";
CM_ SG_ 851 UI_cellReceiverPower "Touchscreen user interface computer: cell receiver power";
CM_ SG_ 851 UI_falseTouchCounter "Count false touches after display is off.";
CM_ SG_ 851 UI_developmentCar "Touchscreen user interface computer: development car";
CM_ SG_ 851 UI_cameraActive "Touchscreen user interface computer: camera active";
CM_ SG_ 851 UI_cellSignalBars "Number of cellular signal bars displayed on the UI, derived from cellSignalStrength; raw 7 = signal not available (SNA)";
CM_ SG_ 851 UI_trailerModeTelltale "Color of the trailer mode telltale";
CM_ SG_ 851 UI_pcbTemperature "PCB digital temp sensor reading in DegC";
CM_ SG_ 851 UI_cpuTemperature "Apollo Lake SOC temperature in DegC";
CM_ BO_ 991 "Touchscreen user interface computer message: status2; forwarded onto this bus by the gateway; frame length from the layout, not yet observed on a vehicle bus";
CM_ SG_ 991 UI_mobileAppStepCount "Touchscreen user interface computer: mobile app step count";
CM_ SG_ 991 UI_userRequestSnapshot "Touchscreen user interface computer: user request snapshot";
CM_ SG_ 991 UI_touchDetected "Touchscreen user interface computer: touch detected";
CM_ SG_ 991 UI_validDeviceForEUSummon "Touchscreen user interface computer: valid device for EU summon";
CM_ SG_ 991 UI_locatedAtHome "Touchscreen user interface computer: located at home";
CM_ SG_ 991 UI_locatedAtWork "Touchscreen user interface computer: located at work";
CM_ SG_ 991 UI_locatedAtFavorite "Touchscreen user interface computer: located at favorite";
CM_ SG_ 991 UI_displayInDarkMode "Touchscreen user interface computer: display in dark mode";
CM_ SG_ 991 UI_userActivity "Indicates user interaction with the center display";
CM_ SG_ 991 UI_activeTouchPoints "Quantity of active touch points on the Center Display";
CM_ SG_ 991 UI_linkState "Connectivity link state";
CM_ SG_ 991 UI_sentryModeState "Touchscreen user interface computer: sentry mode state; raw 6 = signal not available (SNA)";
CM_ SG_ 991 UI_autopilotSentryRequest "whether AP sentry mode should be enabled";
CM_ SG_ 991 UI_mobileAppConnected "Reports if Web Real-Time Communication (WebRTC) connection is connected while summon screen is open on the mobile app.";
CM_ SG_ 991 UI_phoneLeftInCabin "Used for monitoring phone left behind feature";
CM_ SG_ 991 UI_autoshiftDRState "Reports the User Interface (UI) autoshift Drive/Reverse state.";
CM_ SG_ 991 UI_wifiBtModuleType "Reports the type of Wi-Fi and Bluetooth (BT) module.";
CM_ SG_ 991 UI_sohHealthStatus "Touchscreen user interface computer: soh health status";
CM_ SG_ 991 UI_selfParkState "Reports the auto park state changes; raw 255 = signal not available (SNA)";
CM_ SG_ 991 UI_summonDeviceIndex "Reports which device is being used to control summon.";
CM_ SG_ 991 UI_fullScreenMode "Aggregates all situations with which the UI is using the entire screen so stalkless gear controls are not present";
CM_ SG_ 991 UI_sentryModeCameraDetection "Touchscreen user interface computer: sentry mode camera detection";
CM_ SG_ 991 UI_wakeOnIPActive "Touchscreen user interface computer: wake on IP active";
CM_ SG_ 991 UI_sapActive "Touchscreen user interface computer: sap active";
CM_ SG_ 991 UI_sapClients "Touchscreen user interface computer: sap clients";
CM_ SG_ 991 UI_connectivityStandbyActive "Touchscreen user interface computer: connectivity standby active";
CM_ BO_ 988 "Touchscreen user interface computer message: summon goal; forwarded onto this bus by the gateway; frame length from the layout, not yet observed on a vehicle bus";
CM_ SG_ 988 UI_goalLatitude "Touchscreen user interface computer: goal latitude";
CM_ SG_ 988 UI_goalLongitude "Touchscreen user interface computer: goal longitude";
CM_ SG_ 988 UI_goalOrientation "Touchscreen user interface computer: goal orientation";
CM_ BO_ 1064 "Touchscreen user interface computer message: telemetry control; forwarded onto this bus by the gateway; frame length from the layout, not yet observed on a vehicle bus";
CM_ SG_ 1064 UI_TCR_enable "Touchscreen user interface computer: TCR enable";
CM_ SG_ 1064 UI_TCR_moveStateStanding "Touchscreen user interface computer: TCR move state standing";
CM_ SG_ 1064 UI_TCR_moveStateStopped "Touchscreen user interface computer: TCR move state stopped";
CM_ SG_ 1064 UI_TCR_moveStateMoving "Touchscreen user interface computer: TCR move state moving";
CM_ SG_ 1064 UI_TCR_moveStateIndeterm "Touchscreen user interface computer: TCR move state indeterm";
CM_ SG_ 1064 UI_TCR_classConstElem "Touchscreen user interface computer: TCR class const elem";
CM_ SG_ 1064 UI_TCR_classMovingPed "Touchscreen user interface computer: TCR class moving ped";
CM_ SG_ 1064 UI_TCR_classMovingTwoWheel "Touchscreen user interface computer: TCR class moving two wheel";
CM_ SG_ 1064 UI_TCR_classMovingFourWheel "Touchscreen user interface computer: TCR class moving four wheel";
CM_ SG_ 1064 UI_TCR_classUnknown "Touchscreen user interface computer: TCR class unknown";
CM_ SG_ 1064 UI_TCR_downSampleFactor "Touchscreen user interface computer: TCR down sample factor";
CM_ SG_ 1064 UI_TCR_wExist "Touchscreen user interface computer: TCR w exist";
CM_ SG_ 1064 UI_TCR_vehSpeed "Touchscreen user interface computer: TCR veh speed";
CM_ SG_ 1064 UI_TCR_minRCS "Touchscreen user interface computer: TCR min RCS";
CM_ SG_ 1064 UI_TCR_maxDy "Touchscreen user interface computer: TCR max dy";
CM_ SG_ 1064 UI_TCR_maxObjects "Touchscreen user interface computer: TCR max objects";
CM_ SG_ 1064 UI_TCR_maxRoadClass "Touchscreen user interface computer: TCR max road class";
CM_ BO_ 856 "Touchscreen user interface computer message: tpms mode; forwarded onto this bus by the gateway; frame length from the layout, not yet observed on a vehicle bus";
CM_ SG_ 856 UI_TPMSMode "Touchscreen user interface computer: TPMS mode";
CM_ SG_ 856 UI_TPMSLearnIDMode "Touchscreen user interface computer: TPMS learn ID mode";
CM_ SG_ 856 UI_sizeOfWheelSelect "Touchscreen user interface computer: size of wheel select";
CM_ SG_ 856 UI_sizeOfReqCANAutoLearn "Touchscreen user interface computer: size of req CAN auto learn";
CM_ BO_ 952 "Touchscreen user interface computer message: tpms RC psetting; forwarded onto this bus by the gateway; frame length from the layout, not yet observed on a vehicle bus";
CM_ SG_ 952 UI_sendCalibrateTireRequest "Reports UI requests for PMDI to start the tire pressure calibration routine.";
CM_ SG_ 952 UI_setRCPFront "Touchscreen user interface computer: set RCP front";
CM_ SG_ 952 UI_setRCPRear "Touchscreen user interface computer: set RCP rear";
CM_ BO_ 852 "Touchscreen user interface computer message: ui health status; forwarded onto this bus by the gateway; frame length from the layout, not yet observed on a vehicle bus";
CM_ SG_ 852 UI_centerDisplayRunning "is center display running";
CM_ SG_ 852 UI_centerDisplaySM "Touchscreen user interface computer: center display SM";
CM_ SG_ 852 UI_centerDisplayPowerOn "center display power on";
CM_ SG_ 852 UI_centerDisplayCrtcOk "Touchscreen user interface computer: center display crtc ok";
CM_ SG_ 852 UI_centerDisplayHardwareOk "Touchscreen user interface computer: center display hardware ok";
CM_ SG_ 852 UI_centerDisplayWindowManagerOk "Touchscreen user interface computer: center display window manager ok";
CM_ SG_ 852 UI_centerDisplayCompositorOk "Touchscreen user interface computer: center display compositor ok";
CM_ SG_ 852 UI_apVisualizationOk "Touchscreen user interface computer: ap visualization ok";
CM_ SG_ 852 UI_autonomyCenterDispStatus "Touchscreen user interface computer: autonomy center disp status; raw 0 = signal not available (SNA)";
CM_ SG_ 852 UI_autonomyRearDispStatus "Touchscreen user interface computer: autonomy rear disp status; raw 0 = signal not available (SNA)";
CM_ SG_ 852 UI_autonomyConnectivityStatus "Touchscreen user interface computer: autonomy connectivity status; raw 0 = signal not available (SNA)";
CM_ SG_ 852 UI_autonomyConnectivtyHWOk "Touchscreen user interface computer: autonomy connectivty HW ok";
CM_ SG_ 852 UI_autonomyQtCarStatus "Signal reported by Touchscreen user interface computer; raw 0 = signal not available (SNA)";
CM_ SG_ 852 UI_autonomyQtCarRearStatus "Signal reported by Touchscreen user interface computer; raw 0 = signal not available (SNA)";
CM_ SG_ 852 UI_autonomyDASServerStatus "Touchscreen user interface computer: autonomy DAS server status; raw 0 = signal not available (SNA)";
CM_ SG_ 852 UI_rearDisplayRunning "is rear display running";
CM_ SG_ 852 UI_rearDisplayPowerOn "rear display power on";
CM_ SG_ 852 UI_rearDisplaySM "Touchscreen user interface computer: rear display SM";
CM_ SG_ 852 UI_rearDisplayCrtcOk "Touchscreen user interface computer: rear display crtc ok";
CM_ SG_ 852 UI_rearDisplayHardwareOk "Touchscreen user interface computer: rear display hardware ok";
CM_ SG_ 852 UI_rearDisplayWindowManagerOk "Touchscreen user interface computer: rear display window manager ok";
CM_ SG_ 852 UI_rearDisplayCompositorOk "Touchscreen user interface computer: rear display compositor ok";
CM_ BO_ 1827 "Touchscreen user interface computer message: uss thresholds x; forwarded onto this bus by the gateway; frame length from the layout, not yet observed on a vehicle bus";
CM_ SG_ 1827 UI_ussSensorIdX "Touchscreen user interface computer: uss sensor id x";
CM_ SG_ 1827 UI_ussThresholdX0 "Touchscreen user interface computer: uss threshold X0";
CM_ SG_ 1827 UI_ussThresholdX1 "Touchscreen user interface computer: uss threshold X1";
CM_ SG_ 1827 UI_ussThresholdX2 "Touchscreen user interface computer: uss threshold X2";
CM_ SG_ 1827 UI_ussThresholdX3 "Touchscreen user interface computer: uss threshold X3";
CM_ SG_ 1827 UI_ussThresholdX4 "Touchscreen user interface computer: uss threshold X4";
CM_ SG_ 1827 UI_ussThresholdX5 "Touchscreen user interface computer: uss threshold X5";
CM_ SG_ 1827 UI_ussThresholdX6 "Touchscreen user interface computer: uss threshold X6";
CM_ SG_ 1827 UI_ussThresholdX7 "Touchscreen user interface computer: uss threshold X7";
CM_ SG_ 1827 UI_ussThresholdX8 "Touchscreen user interface computer: uss threshold X8";
CM_ SG_ 1827 UI_ussThresholdX9 "Touchscreen user interface computer: uss threshold X9";
CM_ SG_ 1827 UI_ussThresholdX10 "Touchscreen user interface computer: uss threshold X10";
CM_ SG_ 1827 UI_ussThresholdX11 "Touchscreen user interface computer: uss threshold X11";
CM_ SG_ 1827 UI_ussThresholdXControl "Touchscreen user interface computer: uss threshold x control";
CM_ BO_ 1829 "Touchscreen user interface computer message: uss thresholds y; forwarded onto this bus by the gateway; frame length from the layout, not yet observed on a vehicle bus";
CM_ SG_ 1829 UI_ussSensorIdY "Touchscreen user interface computer: uss sensor id y";
CM_ SG_ 1829 UI_ussThresholdY0 "Touchscreen user interface computer: uss threshold Y0";
CM_ SG_ 1829 UI_ussThresholdY1 "Touchscreen user interface computer: uss threshold Y1";
CM_ SG_ 1829 UI_ussThresholdY2 "Touchscreen user interface computer: uss threshold Y2";
CM_ SG_ 1829 UI_ussThresholdY3 "Touchscreen user interface computer: uss threshold Y3";
CM_ SG_ 1829 UI_ussThresholdY4 "Touchscreen user interface computer: uss threshold Y4";
CM_ SG_ 1829 UI_ussThresholdY5 "Touchscreen user interface computer: uss threshold Y5";
CM_ SG_ 1829 UI_ussThresholdY6 "Touchscreen user interface computer: uss threshold Y6";
CM_ SG_ 1829 UI_ussThresholdY7 "Touchscreen user interface computer: uss threshold Y7";
CM_ SG_ 1829 UI_ussThresholdY8 "Touchscreen user interface computer: uss threshold Y8";
CM_ SG_ 1829 UI_ussThresholdY9 "Touchscreen user interface computer: uss threshold Y9";
CM_ SG_ 1829 UI_ussThresholdY10 "Touchscreen user interface computer: uss threshold Y10";
CM_ SG_ 1829 UI_ussThresholdY11 "Touchscreen user interface computer: uss threshold Y11";
CM_ SG_ 1829 UI_ussThresholdYControl "Touchscreen user interface computer: uss threshold y control";
CM_ BO_ 947 "Touchscreen user interface computer message: vehicle control2; forwarded onto this bus by the gateway; frame length from the layout, not yet observed on a vehicle bus";
CM_ SG_ 947 UI_gloveboxRequest "UI request to open the glovebox";
CM_ SG_ 947 UI_trunkRequest "Rear trunk request";
CM_ SG_ 947 UI_UMCUpdateInhibit "Touchscreen user interface computer: UMC update inhibit";
CM_ SG_ 947 UI_WCUpdateInhibit "Touchscreen user interface computer: WC update inhibit";
CM_ SG_ 947 UI_soundHornOnLock "Touchscreen user interface computer: sound horn on lock";
CM_ SG_ 947 UI_locksPanelActive "Touchscreen user interface computer: locks panel active";
CM_ SG_ 947 UI_PINToDriveEnabled "UI customer level request to pin to drive enabled.";
CM_ SG_ 947 UI_PINToDrivePassed "UI customer level request to enable drive with pin passed.";
CM_ SG_ 947 UI_disableMirrorAutoDim "Request to disable side and rear-view mirror auto dim";
CM_ SG_ 947 UI_lightSwitch "Headlight mode; raw 4 = signal not available (SNA)";
CM_ SG_ 947 UI_readyToAddKey "Ready to add key";
CM_ SG_ 947 UI_alarmTriggerRequest "Alarm activation request from UI";
CM_ SG_ 947 UI_VCSECFeature1 "Touchscreen user interface computer: VCSEC feature1";
CM_ SG_ 947 UI_VCLEFTFeature1 "Touchscreen user interface computer: VCLEFT feature1";
CM_ SG_ 947 UI_summonState "Touchscreen user interface computer: summon state; raw 0 = signal not available (SNA)";
CM_ SG_ 947 UI_displayOnForUser "User is present";
CM_ SG_ 947 UI_freeRollModeRequest "Touchscreen user interface computer: free roll mode request";
CM_ SG_ 947 UI_BLEPushNotificationRequest "Reports that the User Interface (UI) wants to talk to a phone and Vehicle Controller Security (VCSEC) should let all connected phones know.";
CM_ SG_ 947 UI_pairKeyQRCodeDisplaying "Touchscreen user interface computer: pair key QR code displaying";
CM_ SG_ 947 UI_keepAutopilotAwake "Reports the request for Vehicle Controller (VC) to keep autopilot awake.";
CM_ SG_ 947 UI_batteryPreconditioningRequest "Requests battery preconditioning.";
CM_ SG_ 947 UI_coastDownMode "Touchscreen user interface computer: coast down mode";
CM_ SG_ 947 UI_autopilotPowerStateRequest "Requests different power states from autopilot ECU depending on feature usage.";
CM_ SG_ 947 UI_shorted12VCellTestMode "Touchscreen user interface computer: shorted12 v cell test mode";
CM_ SG_ 947 UI_autoRollWindowsOnLockEnable "UI customer level request to enable auto-roll windows on lock";
CM_ SG_ 947 UI_virtualPitchSensorOverrideOKF "Touchscreen user interface computer: virtual pitch sensor override OK for aim";
CM_ SG_ 947 UI_conditionalLoggingEnabledVCSE "Touchscreen user interface computer: conditional logging enabled VCSEC";
CM_ SG_ 947 UI_WC3UpdateInhibit "Touchscreen user interface computer: WC3 update inhibit";
CM_ SG_ 947 UI_steeringWheelHeatReq "Request to enable steering wheel heater";
CM_ SG_ 947 UI_disableHorn "Request to disable horn";
CM_ SG_ 947 UI_frontLeftSeatFanReq "Request for front left seat ventilation";
CM_ SG_ 947 UI_frontRightSeatAutoClimateReq "UI setting to enable auto seat heating and cooling for front right seat";
CM_ SG_ 947 UI_frontRightSeatFanReq "Request for front left seat ventilation";
CM_ SG_ 947 UI_3RLeftSeatHeatReq "UI request for third row left seat heater";
CM_ SG_ 947 UI_3RRightSeatHeatReq "UI request for third row right seat heater";
CM_ SG_ 947 UI_sleepFeature1 "Touchscreen user interface computer: sleep feature1";
CM_ SG_ 947 UI_dcr12VThreshold "Touchscreen user interface computer: dcr12 v threshold";
CM_ SG_ 947 UI_frontLeftSeatAutoClimateReq "UI setting to enable auto seat heating and cooling for front left seat";
CM_ SG_ 947 UI_wiperHeaterReq "UI request to enable the wiper heater";
CM_ SG_ 947 UI_tireSeason "Touchscreen user interface computer: tire season";
CM_ SG_ 947 UI_saveTireConfigReq "Touchscreen user interface computer: save tire config req";
CM_ SG_ 947 UI_silentAlarm "Signal indicating alarms should be silenced";
CM_ SG_ 947 UI_sleepFeature2 "Touchscreen user interface computer: sleep feature2";
CM_ BO_ 644 "Touchscreen user interface computer message: vehicle modes; forwarded onto this bus by the gateway; frame length from the layout, not yet observed on a vehicle bus";
CM_ SG_ 644 UI_factoryMode "Touchscreen user interface computer: factory mode";
CM_ SG_ 644 UI_transportMode "Reports UI Transport mode. Distinct from GTW transport mode.";
CM_ SG_ 644 UI_showroomMode "Reports UI showroom mode.";
CM_ SG_ 644 UI_serviceMode "Service diagnostics mode active";
CM_ SG_ 644 UI_isDelivered "Touchscreen user interface computer: is delivered";
CM_ SG_ 644 UI_hasEverBeenDelivered "Touchscreen user interface computer: has ever been delivered";
CM_ SG_ 644 UI_homelinkV2Command0 "Touchscreen user interface computer: homelink V2 command0";
CM_ SG_ 644 UI_homelinkV2Command1 "Touchscreen user interface computer: homelink V2 command1";
CM_ SG_ 644 UI_homelinkV2Command2 "Touchscreen user interface computer: homelink V2 command2";
CM_ SG_ 644 UI_carWashMode "Car Wash Mode";
CM_ SG_ 644 UI_valetMode "Touchscreen user interface computer: valet mode";
CM_ SG_ 644 UI_gameMode "Game mode";
CM_ SG_ 644 UI_diagnosticsAllowed "Touchscreen user interface computer: diagnostics allowed";
CM_ SG_ 644 UI_serviceModePlus "Extended service diagnostics mode active";
CM_ SG_ 644 UI_premiumAmpPowerOff "Premium amplifier power off request";
CM_ SG_ 644 UI_signedCmdHardLocked "Touchscreen user interface computer: signed cmd hard locked";
CM_ SG_ 644 UI_signedCmdServiceMode "Signal reported by Touchscreen user interface computer";
CM_ SG_ 644 UI_closureEasterEggStatus "Touchscreen user interface computer: closure easter egg status";
CM_ SG_ 644 UI_lightShowType "Type of the light show to be run";
CM_ SG_ 644 UI_sohTestRequest "Touchscreen user interface computer: soh test request";
CM_ SG_ 644 UI_upkeepMode "Reports UI Upkeep Mode state.";
CM_ SG_ 644 UI_vehicleModesCounter "Touchscreen user interface computer: vehicle modes counter";
CM_ SG_ 644 UI_vehicleModesChecksum "Touchscreen user interface computer: vehicle modes checksum";
CM_ BO_ 1569 "Touchscreen user interface computer message: weather data service; forwarded onto this bus by the gateway; frame length from the layout, not yet observed on a vehicle bus";
CM_ SG_ 1569 UI_weatherSvcTimeSinceLast "Touchscreen user interface computer: weather svc time since last; raw 127 = signal not available (SNA)";
CM_ SG_ 1569 UI_weatherSvcWindDir "Touchscreen user interface computer: weather svc wind dir; raw 255 = signal not available (SNA)";
CM_ SG_ 1569 UI_weatherSvcTemperature "Touchscreen user interface computer: weather svc temperature; raw 255 = signal not available (SNA)";
CM_ SG_ 1569 UI_weatherSvcHumidity "Touchscreen user interface computer: weather svc humidity; raw 63 = signal not available (SNA)";
CM_ SG_ 1569 UI_weatherSvcDewPoint "Touchscreen user interface computer: weather svc dew point; raw 255 = signal not available (SNA)";
CM_ SG_ 1569 UI_weatherSvcCloudCover "Touchscreen user interface computer: weather svc cloud cover; raw 63 = signal not available (SNA)";
CM_ SG_ 1569 UI_weatherSvcPrecipProb "Touchscreen user interface computer: weather svc precip prob; raw 63 = signal not available (SNA)";
CM_ SG_ 1569 UI_weatherSvcRaining "Touchscreen user interface computer: weather svc raining";
CM_ SG_ 1569 UI_weatherSvcSnowing "Touchscreen user interface computer: weather svc snowing";
CM_ SG_ 1569 UI_weatherSvcWindSpeed "Touchscreen user interface computer: weather svc wind speed; raw 63 = signal not available (SNA)";
BA_DEF_ BO_ "GenMsgCycleTime" INT 0 3600000;
BA_DEF_ BO_ "GenMsgSendType" ENUM "Cyclic","NotUsed","NotUsed","NotUsed","NotUsed","NotUsed","NotUsed","IfActive","NoMsgSendType","NotUsed";
BA_DEF_ BO_ "VFrameFormat" ENUM "StandardCAN","ExtendedCAN","reserved","J1939PG","reserved","reserved","reserved","reserved","reserved","reserved","reserved","reserved","reserved","reserved","StandardCAN_FD","ExtendedCAN_FD";
BA_DEF_ BO_ "CANFD_BRS" ENUM "0","1";
BA_DEF_ SG_ "GenSigSNA" STRING;
BA_DEF_ SG_ "SystemSignalLongSymbol" STRING;
BA_DEF_ SG_ "Confidence" ENUM "validated","plausible","layout-only","contradicted";
BA_DEF_DEF_ "GenMsgCycleTime" 0;
BA_DEF_DEF_ "GenMsgSendType" "NoMsgSendType";
BA_DEF_DEF_ "VFrameFormat" "StandardCAN";
BA_DEF_DEF_ "CANFD_BRS" "1";
BA_DEF_DEF_ "GenSigSNA" "";
BA_DEF_DEF_ "SystemSignalLongSymbol" "";
BA_DEF_DEF_ "Confidence" "layout-only";
BA_ "GenMsgCycleTime" BO_ 679 500;
BA_ "GenMsgSendType" BO_ 679 0;
BA_ "GenMsgCycleTime" BO_ 1096 1000;
BA_ "GenMsgSendType" BO_ 1096 0;
BA_ "GenMsgCycleTime" BO_ 1016 1000;
BA_ "GenMsgSendType" BO_ 1016 0;
BA_ "GenMsgCycleTime" BO_ 568 500;
BA_ "GenMsgSendType" BO_ 568 0;
BA_ "GenMsgCycleTime" BO_ 536 500;
BA_ "GenMsgSendType" BO_ 536 0;
BA_ "GenMsgCycleTime" BO_ 1971 500;
BA_ "GenMsgSendType" BO_ 1971 0;
BA_ "GenMsgCycleTime" BO_ 760 1000;
BA_ "GenMsgSendType" BO_ 760 0;
BA_ "GenMsgCycleTime" BO_ 985 1000;
BA_ "GenMsgSendType" BO_ 985 0;
BA_ "GenMsgCycleTime" BO_ 777 1000;
BA_ "GenMsgSendType" BO_ 777 0;
BA_ "GenMsgCycleTime" BO_ 1011 1000;
BA_ "GenMsgSendType" BO_ 1011 0;
BA_ "GenMsgCycleTime" BO_ 987 1000;
BA_ "GenMsgSendType" BO_ 987 0;
BA_ "GenMsgCycleTime" BO_ 820 500;
BA_ "GenMsgSendType" BO_ 820 0;
BA_ "GenMsgCycleTime" BO_ 698 500;
BA_ "GenMsgSendType" BO_ 698 0;
BA_ "GenMsgCycleTime" BO_ 632 500;
BA_ "GenMsgSendType" BO_ 632 0;
BA_ "GenMsgCycleTime" BO_ 723 1000;
BA_ "GenMsgSendType" BO_ 723 0;
BA_ "GenMsgCycleTime" BO_ 851 500;
BA_ "GenMsgSendType" BO_ 851 0;
BA_ "GenMsgCycleTime" BO_ 991 500;
BA_ "GenMsgSendType" BO_ 991 0;
BA_ "GenMsgCycleTime" BO_ 988 1000;
BA_ "GenMsgSendType" BO_ 988 0;
BA_ "GenMsgCycleTime" BO_ 1064 1000;
BA_ "GenMsgSendType" BO_ 1064 0;
BA_ "GenMsgCycleTime" BO_ 952 1000;
BA_ "GenMsgSendType" BO_ 952 0;
BA_ "GenMsgCycleTime" BO_ 852 500;
BA_ "GenMsgSendType" BO_ 852 0;
BA_ "GenMsgCycleTime" BO_ 947 500;
BA_ "GenMsgSendType" BO_ 947 0;
BA_ "GenMsgCycleTime" BO_ 644 500;
BA_ "GenMsgSendType" BO_ 644 0;
BA_ "GenMsgCycleTime" BO_ 1569 500;
BA_ "GenMsgSendType" BO_ 1569 0;
BA_ "Confidence" SG_ 679 UI_csaRoadCurvC2 1;
BA_ "Confidence" SG_ 679 UI_csaRoadCurvC3 1;
BA_ "Confidence" SG_ 679 UI_csaRoadCurvRange 1;
BA_ "Confidence" SG_ 1096 UI_anonDebugFlag1 1;
BA_ "Confidence" SG_ 1096 UI_anonDebugFlag2 1;
BA_ "Confidence" SG_ 1096 UI_anonDebugFlag3 1;
BA_ "Confidence" SG_ 1096 UI_anonDebugFlag4 1;
BA_ "Confidence" SG_ 1016 UI_autopilotControlRequest 1;
BA_ "Confidence" SG_ 1016 UI_ulcStalkConfirm 0;
BA_ "Confidence" SG_ 1016 UI_curvSpeedAdaptDisable 1;
BA_ "Confidence" SG_ 1016 UI_lssLkaEnabled 0;
BA_ "Confidence" SG_ 1016 UI_lssLdwEnabled 0;
BA_ "Confidence" SG_ 1016 UI_exceptionListEnable 1;
BA_ "Confidence" SG_ 1016 UI_roadCheckDisable 1;
BA_ "Confidence" SG_ 1016 UI_driveOnMapsEnable 0;
BA_ "Confidence" SG_ 1016 UI_handsOnRequirementDisable 1;
BA_ "Confidence" SG_ 1016 UI_fuseLanesDisable 1;
BA_ "Confidence" SG_ 1016 UI_fuseHPPDisable 1;
BA_ "Confidence" SG_ 1016 UI_fuseVehiclesDisable 1;
BA_ "Confidence" SG_ 1016 UI_visionSpeedType 1;
BA_ "Confidence" SG_ 1016 UI_curvatureDatabaseOnly 1;
BA_ "Confidence" SG_ 1016 UI_lssElkEnabled 0;
BA_ "Confidence" SG_ 1016 UI_summonExitType 1;
BA_ "GenSigSNA" SG_ 1016 UI_summonExitType "3";
BA_ "Confidence" SG_ 1016 UI_summonEntryType 1;
BA_ "GenSigSNA" SG_ 1016 UI_summonEntryType "3";
BA_ "Confidence" SG_ 1016 UI_selfParkRequest 0;
BA_ "GenSigSNA" SG_ 1016 UI_selfParkRequest "15";
BA_ "Confidence" SG_ 1016 UI_summonReverseDist 1;
BA_ "GenSigSNA" SG_ 1016 UI_summonReverseDist "63";
BA_ "Confidence" SG_ 1016 UI_drivingSide 1;
BA_ "Confidence" SG_ 1016 UI_accFollowDistanceSetting 1;
BA_ "GenSigSNA" SG_ 1016 UI_accFollowDistanceSetting "7";
BA_ "Confidence" SG_ 1016 UI_followNavRouteEnable 0;
BA_ "Confidence" SG_ 1016 UI_ulcSpeedConfig 0;
BA_ "Confidence" SG_ 1016 UI_ulcBlindSpotConfig 1;
BA_ "Confidence" SG_ 1016 UI_suppressExitPassingLane 0;
BA_ "Confidence" SG_ 1016 UI_smartSummonType 0;
BA_ "Confidence" SG_ 1016 UI_source3D 1;
BA_ "Confidence" SG_ 1016 UI_isaSpeedingChimeMuted 0;
BA_ "Confidence" SG_ 568 UI_mapSpeedLimitDependency 1;
BA_ "GenSigSNA" SG_ 568 UI_mapSpeedLimitDependency "7";
BA_ "Confidence" SG_ 568 UI_roadClass 0;
BA_ "GenSigSNA" SG_ 568 UI_roadClass "0";
BA_ "Confidence" SG_ 568 UI_inSuperchargerGeofence 1;
BA_ "Confidence" SG_ 568 UI_mapSpeedUnits 1;
BA_ "Confidence" SG_ 568 UI_mapSpeedLimit 1;
BA_ "GenSigSNA" SG_ 568 UI_mapSpeedLimit "31";
BA_ "Confidence" SG_ 568 UI_mapSpeedLimitType 1;
BA_ "GenSigSNA" SG_ 568 UI_mapSpeedLimitType "7";
BA_ "Confidence" SG_ 568 UI_countryCode 1;
BA_ "GenSigSNA" SG_ 568 UI_countryCode "1023";
BA_ "Confidence" SG_ 568 UI_streetCount 1;
BA_ "Confidence" SG_ 568 UI_gpsRoadMatch 1;
BA_ "Confidence" SG_ 568 UI_navRouteActive 0;
BA_ "Confidence" SG_ 568 UI_parallelAutoparkEnabled 0;
BA_ "Confidence" SG_ 568 UI_perpendicularAutoparkEnabled 0;
BA_ "Confidence" SG_ 568 UI_nextBranchDist 1;
BA_ "GenSigSNA" SG_ 568 UI_nextBranchDist "31";
BA_ "Confidence" SG_ 568 UI_controlledAccess 0;
BA_ "Confidence" SG_ 568 UI_nextBranchLeftOffRamp 1;
BA_ "Confidence" SG_ 568 UI_nextBranchRightOffRamp 1;
BA_ "Confidence" SG_ 568 UI_rejectLeftLane 1;
BA_ "Confidence" SG_ 568 UI_rejectRightLane 1;
BA_ "Confidence" SG_ 568 UI_rejectHPP 1;
BA_ "Confidence" SG_ 568 UI_rejectNav 1;
BA_ "Confidence" SG_ 568 UI_rejectLeftFreeSpace 1;
BA_ "Confidence" SG_ 568 UI_rejectRightFreeSpace 1;
BA_ "Confidence" SG_ 568 UI_rejectAutosteer 1;
BA_ "Confidence" SG_ 568 UI_rejectHandsOn 1;
BA_ "Confidence" SG_ 568 UI_acceptBottsDots 1;
BA_ "Confidence" SG_ 568 UI_autosteerRestricted 0;
BA_ "Confidence" SG_ 568 UI_pmmEnabled 1;
BA_ "Confidence" SG_ 568 UI_scaEnabled 1;
BA_ "Confidence" SG_ 568 UI_mapDataCounter 1;
BA_ "Confidence" SG_ 568 UI_mapDataChecksum 0;
BA_ "Confidence" SG_ 536 UI_roadSign 1;
BA_ "GenSigSNA" SG_ 536 UI_roadSign "255";
BA_ "Confidence" SG_ 536 UI_splineLocConfidence 1;
BA_ "GenSigSNA" SG_ 536 UI_splineLocConfidence "0";
BA_ "Confidence" SG_ 536 UI_stopSignStopLineDist 1;
BA_ "GenSigSNA" SG_ 536 UI_stopSignStopLineDist "1023";
BA_ "Confidence" SG_ 536 UI_stopSignStopLineConf 1;
BA_ "GenSigSNA" SG_ 536 UI_stopSignStopLineConf "0";
BA_ "Confidence" SG_ 536 UI_trafficLightStopLineDist 1;
BA_ "GenSigSNA" SG_ 536 UI_trafficLightStopLineDist "1023";
BA_ "Confidence" SG_ 536 UI_trafficLightStopLineConf 1;
BA_ "GenSigSNA" SG_ 536 UI_trafficLightStopLineConf "0";
BA_ "Confidence" SG_ 536 UI_baseMapSpeedLimitMPS 1;
BA_ "GenSigSNA" SG_ 536 UI_baseMapSpeedLimitMPS "255";
BA_ "Confidence" SG_ 536 UI_bottomQrtlFleetSpeedMPS 1;
BA_ "GenSigSNA" SG_ 536 UI_bottomQrtlFleetSpeedMPS "255";
BA_ "Confidence" SG_ 536 UI_topQrtlFleetSpeedMPS 1;
BA_ "GenSigSNA" SG_ 536 UI_topQrtlFleetSpeedMPS "255";
BA_ "Confidence" SG_ 536 UI_meanFleetSplineSpeedMPS 1;
BA_ "GenSigSNA" SG_ 536 UI_meanFleetSplineSpeedMPS "255";
BA_ "Confidence" SG_ 536 UI_medianFleetSpeedMPS 1;
BA_ "GenSigSNA" SG_ 536 UI_medianFleetSpeedMPS "255";
BA_ "Confidence" SG_ 536 UI_meanFleetSplineAccelMPS2 1;
BA_ "GenSigSNA" SG_ 536 UI_meanFleetSplineAccelMPS2 "255";
BA_ "Confidence" SG_ 536 UI_rampType 1;
BA_ "GenSigSNA" SG_ 536 UI_rampType "0";
BA_ "Confidence" SG_ 536 UI_valhallaRamp 1;
BA_ "GenSigSNA" SG_ 536 UI_valhallaRamp "0";
BA_ "Confidence" SG_ 536 UI_currSplineIdFull 1;
BA_ "GenSigSNA" SG_ 536 UI_currSplineIdFull "0";
BA_ "Confidence" SG_ 760 UI_gpsHDOP 1;
BA_ "Confidence" SG_ 760 UI_gpsVehicleHeading 1;
BA_ "Confidence" SG_ 760 UI_gpsVehicleSpeed 1;
BA_ "Confidence" SG_ 760 UI_userSpeedOffset 1;
BA_ "Confidence" SG_ 760 UI_mapSpeedLimitUnits 0;
BA_ "Confidence" SG_ 760 UI_userSpeedOffsetUnits 1;
BA_ "Confidence" SG_ 760 UI_mppSpeedLimit 0;
BA_ "Confidence" SG_ 760 UI_gpsNmeaMIA 0;
BA_ "Confidence" SG_ 760 UI_gpsAntennaDisconnected 0;
BA_ "Confidence" SG_ 760 UI_conditionalLimitActive 0;
BA_ "Confidence" SG_ 760 UI_conditionalSpeedLimit 0;
BA_ "GenSigSNA" SG_ 760 UI_conditionalSpeedLimit "31";
BA_ "Confidence" SG_ 985 UI_latitudeOffset 1;
BA_ "Confidence" SG_ 985 UI_longitudeOffset 1;
BA_ "Confidence" SG_ 777 UI_latitude 1;
BA_ "Confidence" SG_ 777 UI_longitude 1;
BA_ "Confidence" SG_ 777 UI_gpsAccuracy 1;
BA_ "GenSigSNA" SG_ 777 UI_gpsAccuracy "127";
BA_ "Confidence" SG_ 1011 UI_odometer 0;
BA_ "GenSigSNA" SG_ 1011 UI_odometer "16777215";
BA_ "Confidence" SG_ 987 UI_phoneLatitude 1;
BA_ "Confidence" SG_ 987 UI_phoneLongitude 1;
BA_ "Confidence" SG_ 987 UI_phoneGpsAccuracy 1;
BA_ "GenSigSNA" SG_ 987 UI_phoneGpsAccuracy "127";
BA_ "Confidence" SG_ 820 UI_systemPowerLimit 1;
BA_ "GenSigSNA" SG_ 820 UI_systemPowerLimit "31";
BA_ "Confidence" SG_ 820 UI_pedalMap 0;
BA_ "Confidence" SG_ 820 UI_enableRegenBackfill 0;
BA_ "Confidence" SG_ 820 UI_systemTorqueLimit 1;
BA_ "GenSigSNA" SG_ 820 UI_systemTorqueLimit "63";
BA_ "Confidence" SG_ 820 UI_closureConfirmed 1;
BA_ "Confidence" SG_ 820 UI_regenTorqueMax 0;
BA_ "Confidence" SG_ 820 UI_limitMode 0;
BA_ "Confidence" SG_ 820 UI_factoryCustomerDrivingModeReq 1;
BA_ "SystemSignalLongSymbol" SG_ 820 UI_factoryCustomerDrivingModeReq "UI_factoryCustomerDrivingModeRequest";
BA_ "Confidence" SG_ 820 UI_motorOnMode 0;
BA_ "Confidence" SG_ 820 UI_stoppingMode 0;
BA_ "Confidence" SG_ 820 UI_DIAppSliderDebug 1;
BA_ "Confidence" SG_ 820 UI_speedLimit 0;
BA_ "GenSigSNA" SG_ 820 UI_speedLimit "511";
BA_ "Confidence" SG_ 820 UI_enableSmartShift 0;
BA_ "Confidence" SG_ 820 UI_navVehParallelToRdCanContinue 0;
BA_ "GenSigSNA" SG_ 820 UI_navVehParallelToRdCanContinue "0";
BA_ "Confidence" SG_ 820 UI_powertrainControlCounter 1;
BA_ "Confidence" SG_ 820 UI_powertrainControlChecksum 0;
BA_ "Confidence" SG_ 698 UI_radarTargetDx 1;
BA_ "Confidence" SG_ 698 UI_radarTargetDxEnd 1;
BA_ "Confidence" SG_ 632 UI_roadCurvC0 1;
BA_ "Confidence" SG_ 632 UI_roadCurvC1 1;
BA_ "Confidence" SG_ 632 UI_roadCurvC2 1;
BA_ "Confidence" SG_ 632 UI_roadCurvC3 1;
BA_ "Confidence" SG_ 632 UI_roadCurvRange 1;
BA_ "Confidence" SG_ 632 UI_roadCurvHealth 1;
BA_ "Confidence" SG_ 723 UI_solarAzimuthAngle 1;
BA_ "GenSigSNA" SG_ 723 UI_solarAzimuthAngle "32768";
BA_ "Confidence" SG_ 723 UI_solarAzimuthAngleCarRef 1;
BA_ "GenSigSNA" SG_ 723 UI_solarAzimuthAngleCarRef "255";
BA_ "Confidence" SG_ 723 UI_isSunUp 0;
BA_ "GenSigSNA" SG_ 723 UI_isSunUp "3";
BA_ "Confidence" SG_ 723 UI_solarElevationAngle 0;
BA_ "GenSigSNA" SG_ 723 UI_solarElevationAngle "127";
BA_ "Confidence" SG_ 723 UI_screenPCBTemperature 0;
BA_ "Confidence" SG_ 723 UI_minsToSunset 0;
BA_ "Confidence" SG_ 723 UI_minsToSunrise 0;
BA_ "Confidence" SG_ 851 UI_touchActive 0;
BA_ "Confidence" SG_ 851 UI_audioActive 0;
BA_ "Confidence" SG_ 851 UI_bluetoothActive 1;
BA_ "Confidence" SG_ 851 UI_cellActive 0;
BA_ "Confidence" SG_ 851 UI_displayReady 0;
BA_ "Confidence" SG_ 851 UI_displayOn 0;
BA_ "Confidence" SG_ 851 UI_wifiActive 0;
BA_ "Confidence" SG_ 851 UI_wifiConnected 0;
BA_ "Confidence" SG_ 851 UI_systemActive 1;
BA_ "Confidence" SG_ 851 UI_readyForDrive 0;
BA_ "Confidence" SG_ 851 UI_cellConnected 0;
BA_ "Confidence" SG_ 851 UI_vpnActive 0;
BA_ "Confidence" SG_ 851 UI_autopilotTrial 1;
BA_ "Confidence" SG_ 851 UI_factoryReset 0;
BA_ "GenSigSNA" SG_ 851 UI_factoryReset "0";
BA_ "Confidence" SG_ 851 UI_gpsActive 0;
BA_ "Confidence" SG_ 851 UI_screenshotActive 1;
BA_ "Confidence" SG_ 851 UI_radioActive 1;
BA_ "Confidence" SG_ 851 UI_cellNetworkTechnology 0;
BA_ "GenSigSNA" SG_ 851 UI_cellNetworkTechnology "15";
BA_ "Confidence" SG_ 851 UI_cellReceiverPower 1;
BA_ "Confidence" SG_ 851 UI_falseTouchCounter 0;
BA_ "Confidence" SG_ 851 UI_developmentCar 1;
BA_ "Confidence" SG_ 851 UI_cameraActive 1;
BA_ "Confidence" SG_ 851 UI_cellSignalBars 0;
BA_ "GenSigSNA" SG_ 851 UI_cellSignalBars "7";
BA_ "Confidence" SG_ 851 UI_trailerModeTelltale 0;
BA_ "Confidence" SG_ 851 UI_pcbTemperature 0;
BA_ "Confidence" SG_ 851 UI_cpuTemperature 0;
BA_ "Confidence" SG_ 991 UI_mobileAppStepCount 1;
BA_ "Confidence" SG_ 991 UI_userRequestSnapshot 1;
BA_ "Confidence" SG_ 991 UI_touchDetected 1;
BA_ "Confidence" SG_ 991 UI_validDeviceForEUSummon 1;
BA_ "Confidence" SG_ 991 UI_locatedAtHome 1;
BA_ "Confidence" SG_ 991 UI_locatedAtWork 1;
BA_ "Confidence" SG_ 991 UI_locatedAtFavorite 1;
BA_ "Confidence" SG_ 991 UI_displayInDarkMode 1;
BA_ "Confidence" SG_ 991 UI_userActivity 0;
BA_ "Confidence" SG_ 991 UI_activeTouchPoints 0;
BA_ "Confidence" SG_ 991 UI_linkState 0;
BA_ "Confidence" SG_ 991 UI_sentryModeState 1;
BA_ "GenSigSNA" SG_ 991 UI_sentryModeState "6";
BA_ "Confidence" SG_ 991 UI_autopilotSentryRequest 0;
BA_ "Confidence" SG_ 991 UI_mobileAppConnected 0;
BA_ "Confidence" SG_ 991 UI_phoneLeftInCabin 0;
BA_ "Confidence" SG_ 991 UI_autoshiftDRState 0;
BA_ "Confidence" SG_ 991 UI_wifiBtModuleType 0;
BA_ "Confidence" SG_ 991 UI_sohHealthStatus 1;
BA_ "Confidence" SG_ 991 UI_selfParkState 0;
BA_ "GenSigSNA" SG_ 991 UI_selfParkState "255";
BA_ "Confidence" SG_ 991 UI_summonDeviceIndex 0;
BA_ "Confidence" SG_ 991 UI_fullScreenMode 0;
BA_ "Confidence" SG_ 991 UI_sentryModeCameraDetection 1;
BA_ "Confidence" SG_ 991 UI_wakeOnIPActive 1;
BA_ "Confidence" SG_ 991 UI_sapActive 1;
BA_ "Confidence" SG_ 991 UI_sapClients 1;
BA_ "Confidence" SG_ 991 UI_connectivityStandbyActive 1;
BA_ "Confidence" SG_ 988 UI_goalLatitude 1;
BA_ "Confidence" SG_ 988 UI_goalLongitude 1;
BA_ "Confidence" SG_ 988 UI_goalOrientation 1;
BA_ "Confidence" SG_ 1064 UI_TCR_minRCS 1;
BA_ "Confidence" SG_ 1064 UI_TCR_maxDy 1;
BA_ "Confidence" SG_ 856 UI_TPMSMode 1;
BA_ "Confidence" SG_ 856 UI_TPMSLearnIDMode 1;
BA_ "Confidence" SG_ 856 UI_sizeOfWheelSelect 1;
BA_ "Confidence" SG_ 952 UI_sendCalibrateTireRequest 0;
BA_ "Confidence" SG_ 952 UI_setRCPFront 1;
BA_ "Confidence" SG_ 952 UI_setRCPRear 1;
BA_ "Confidence" SG_ 852 UI_centerDisplayRunning 0;
BA_ "Confidence" SG_ 852 UI_centerDisplaySM 1;
BA_ "Confidence" SG_ 852 UI_centerDisplayPowerOn 0;
BA_ "Confidence" SG_ 852 UI_autonomyCenterDispStatus 1;
BA_ "GenSigSNA" SG_ 852 UI_autonomyCenterDispStatus "0";
BA_ "Confidence" SG_ 852 UI_autonomyRearDispStatus 1;
BA_ "GenSigSNA" SG_ 852 UI_autonomyRearDispStatus "0";
BA_ "Confidence" SG_ 852 UI_autonomyConnectivityStatus 1;
BA_ "GenSigSNA" SG_ 852 UI_autonomyConnectivityStatus "0";
BA_ "Confidence" SG_ 852 UI_autonomyQtCarStatus 1;
BA_ "GenSigSNA" SG_ 852 UI_autonomyQtCarStatus "0";
BA_ "Confidence" SG_ 852 UI_autonomyQtCarRearStatus 1;
BA_ "GenSigSNA" SG_ 852 UI_autonomyQtCarRearStatus "0";
BA_ "Confidence" SG_ 852 UI_autonomyDASServerStatus 1;
BA_ "GenSigSNA" SG_ 852 UI_autonomyDASServerStatus "0";
BA_ "Confidence" SG_ 852 UI_rearDisplayRunning 0;
BA_ "Confidence" SG_ 852 UI_rearDisplayPowerOn 0;
BA_ "Confidence" SG_ 852 UI_rearDisplaySM 1;
BA_ "Confidence" SG_ 1827 UI_ussSensorIdX 1;
BA_ "Confidence" SG_ 1829 UI_ussSensorIdY 1;
BA_ "Confidence" SG_ 947 UI_gloveboxRequest 0;
BA_ "Confidence" SG_ 947 UI_trunkRequest 0;
BA_ "Confidence" SG_ 947 UI_UMCUpdateInhibit 1;
BA_ "Confidence" SG_ 947 UI_WCUpdateInhibit 1;
BA_ "Confidence" SG_ 947 UI_soundHornOnLock 1;
BA_ "Confidence" SG_ 947 UI_locksPanelActive 1;
BA_ "Confidence" SG_ 947 UI_PINToDriveEnabled 0;
BA_ "Confidence" SG_ 947 UI_PINToDrivePassed 0;
BA_ "Confidence" SG_ 947 UI_disableMirrorAutoDim 0;
BA_ "Confidence" SG_ 947 UI_lightSwitch 0;
BA_ "GenSigSNA" SG_ 947 UI_lightSwitch "4";
BA_ "Confidence" SG_ 947 UI_readyToAddKey 0;
BA_ "Confidence" SG_ 947 UI_alarmTriggerRequest 0;
BA_ "Confidence" SG_ 947 UI_VCSECFeature1 1;
BA_ "Confidence" SG_ 947 UI_VCLEFTFeature1 1;
BA_ "Confidence" SG_ 947 UI_summonState 1;
BA_ "GenSigSNA" SG_ 947 UI_summonState "0";
BA_ "Confidence" SG_ 947 UI_displayOnForUser 0;
BA_ "Confidence" SG_ 947 UI_freeRollModeRequest 1;
BA_ "Confidence" SG_ 947 UI_BLEPushNotificationRequest 0;
BA_ "Confidence" SG_ 947 UI_pairKeyQRCodeDisplaying 1;
BA_ "Confidence" SG_ 947 UI_keepAutopilotAwake 0;
BA_ "Confidence" SG_ 947 UI_batteryPreconditioningRequest 0;
BA_ "Confidence" SG_ 947 UI_coastDownMode 1;
BA_ "Confidence" SG_ 947 UI_autopilotPowerStateRequest 0;
BA_ "Confidence" SG_ 947 UI_shorted12VCellTestMode 1;
BA_ "Confidence" SG_ 947 UI_autoRollWindowsOnLockEnable 0;
BA_ "Confidence" SG_ 947 UI_virtualPitchSensorOverrideOKF 1;
BA_ "SystemSignalLongSymbol" SG_ 947 UI_virtualPitchSensorOverrideOKF "UI_virtualPitchSensorOverrideOKForAim";
BA_ "Confidence" SG_ 947 UI_conditionalLoggingEnabledVCSE 1;
BA_ "SystemSignalLongSymbol" SG_ 947 UI_conditionalLoggingEnabledVCSE "UI_conditionalLoggingEnabledVCSEC";
BA_ "Confidence" SG_ 947 UI_WC3UpdateInhibit 1;
BA_ "Confidence" SG_ 947 UI_steeringWheelHeatReq 0;
BA_ "Confidence" SG_ 947 UI_disableHorn 0;
BA_ "Confidence" SG_ 947 UI_frontLeftSeatFanReq 0;
BA_ "Confidence" SG_ 947 UI_frontRightSeatAutoClimateReq 0;
BA_ "Confidence" SG_ 947 UI_frontRightSeatFanReq 0;
BA_ "Confidence" SG_ 947 UI_3RLeftSeatHeatReq 0;
BA_ "Confidence" SG_ 947 UI_3RRightSeatHeatReq 0;
BA_ "Confidence" SG_ 947 UI_sleepFeature1 1;
BA_ "Confidence" SG_ 947 UI_dcr12VThreshold 1;
BA_ "Confidence" SG_ 947 UI_frontLeftSeatAutoClimateReq 0;
BA_ "Confidence" SG_ 947 UI_wiperHeaterReq 0;
BA_ "Confidence" SG_ 947 UI_tireSeason 1;
BA_ "Confidence" SG_ 947 UI_saveTireConfigReq 1;
BA_ "Confidence" SG_ 947 UI_silentAlarm 0;
BA_ "Confidence" SG_ 947 UI_sleepFeature2 1;
BA_ "Confidence" SG_ 644 UI_factoryMode 1;
BA_ "Confidence" SG_ 644 UI_transportMode 0;
BA_ "Confidence" SG_ 644 UI_showroomMode 0;
BA_ "Confidence" SG_ 644 UI_serviceMode 0;
BA_ "Confidence" SG_ 644 UI_isDelivered 1;
BA_ "Confidence" SG_ 644 UI_hasEverBeenDelivered 1;
BA_ "Confidence" SG_ 644 UI_homelinkV2Command0 1;
BA_ "Confidence" SG_ 644 UI_homelinkV2Command1 1;
BA_ "Confidence" SG_ 644 UI_homelinkV2Command2 1;
BA_ "Confidence" SG_ 644 UI_carWashMode 0;
BA_ "Confidence" SG_ 644 UI_valetMode 1;
BA_ "Confidence" SG_ 644 UI_gameMode 0;
BA_ "Confidence" SG_ 644 UI_diagnosticsAllowed 1;
BA_ "Confidence" SG_ 644 UI_serviceModePlus 0;
BA_ "Confidence" SG_ 644 UI_premiumAmpPowerOff 0;
BA_ "Confidence" SG_ 644 UI_signedCmdHardLocked 1;
BA_ "Confidence" SG_ 644 UI_signedCmdServiceMode 1;
BA_ "Confidence" SG_ 644 UI_closureEasterEggStatus 1;
BA_ "Confidence" SG_ 644 UI_lightShowType 0;
BA_ "Confidence" SG_ 644 UI_sohTestRequest 1;
BA_ "Confidence" SG_ 644 UI_upkeepMode 0;
BA_ "Confidence" SG_ 644 UI_vehicleModesCounter 1;
BA_ "Confidence" SG_ 644 UI_vehicleModesChecksum 0;
BA_ "Confidence" SG_ 1569 UI_weatherSvcTimeSinceLast 1;
BA_ "GenSigSNA" SG_ 1569 UI_weatherSvcTimeSinceLast "127";
BA_ "Confidence" SG_ 1569 UI_weatherSvcWindDir 1;
BA_ "GenSigSNA" SG_ 1569 UI_weatherSvcWindDir "255";
BA_ "Confidence" SG_ 1569 UI_weatherSvcTemperature 1;
BA_ "GenSigSNA" SG_ 1569 UI_weatherSvcTemperature "255";
BA_ "Confidence" SG_ 1569 UI_weatherSvcHumidity 1;
BA_ "GenSigSNA" SG_ 1569 UI_weatherSvcHumidity "63";
BA_ "Confidence" SG_ 1569 UI_weatherSvcDewPoint 1;
BA_ "GenSigSNA" SG_ 1569 UI_weatherSvcDewPoint "255";
BA_ "Confidence" SG_ 1569 UI_weatherSvcCloudCover 1;
BA_ "GenSigSNA" SG_ 1569 UI_weatherSvcCloudCover "63";
BA_ "Confidence" SG_ 1569 UI_weatherSvcPrecipProb 1;
BA_ "GenSigSNA" SG_ 1569 UI_weatherSvcPrecipProb "63";
BA_ "Confidence" SG_ 1569 UI_weatherSvcRaining 1;
BA_ "Confidence" SG_ 1569 UI_weatherSvcSnowing 1;
BA_ "Confidence" SG_ 1569 UI_weatherSvcWindSpeed 1;
BA_ "GenSigSNA" SG_ 1569 UI_weatherSvcWindSpeed "63";
VAL_ 1096 UI_anonDebugFlag1 1 "ON" 0 "OFF" ;
VAL_ 1096 UI_anonDebugFlag2 1 "ON" 0 "OFF" ;
VAL_ 1096 UI_anonDebugFlag3 1 "ON" 0 "OFF" ;
VAL_ 1096 UI_anonDebugFlag4 1 "ON" 0 "OFF" ;
VAL_ 1016 UI_autopilotControlRequest 1 "NEXT_GEN_CTRL" 0 "LEGACY_LAT_CTRL" ;
VAL_ 1016 UI_curvSpeedAdaptDisable 1 "OFF" 0 "ON" ;
VAL_ 1016 UI_lssLkaEnabled 1 "LKA_ON" 0 "LKA_OFF" ;
VAL_ 1016 UI_lssLdwEnabled 1 "LDW_ON" 0 "LDW_OFF" ;
VAL_ 1016 UI_exceptionListEnable 1 "ON" 0 "OFF" ;
VAL_ 1016 UI_roadCheckDisable 1 "OFF" 0 "ON" ;
VAL_ 1016 UI_driveOnMapsEnable 1 "DOM_ON" 0 "DOM_OFF" ;
VAL_ 1016 UI_handsOnRequirementDisable 1 "OFF" 0 "ON" ;
VAL_ 1016 UI_fuseLanesDisable 1 "OFF" 0 "ON" ;
VAL_ 1016 UI_fuseHPPDisable 1 "OFF" 0 "ON" ;
VAL_ 1016 UI_fuseVehiclesDisable 1 "OFF" 0 "ON" ;
VAL_ 1016 UI_visionSpeedType 3 "OPTIMIZED" 2 "TWO_SECOND" 1 "ONE_SECOND" 0 "DISABLED" ;
VAL_ 1016 UI_curvatureDatabaseOnly 1 "ON" 0 "OFF" ;
VAL_ 1016 UI_lssElkEnabled 1 "ELK_ON" 0 "ELK_OFF" ;
VAL_ 1016 UI_summonExitType 3 "SNA" 2 "TURN_LEFT" 1 "TURN_RIGHT" 0 "STRAIGHT" ;
VAL_ 1016 UI_summonEntryType 3 "SNA" 2 "TURN_LEFT" 1 "TURN_RIGHT" 0 "STRAIGHT" ;
VAL_ 1016 UI_selfParkRequest 15 "SNA" 12 "SMART_SUMMON_NO_OP" 11 "SMART_SUMMON" 10 "AUTO_SUMMON_PRIMED" 9 "AUTO_SUMMON_CANCEL" 8 "AUTO_SUMMON_REVERSE" 7 "AUTO_SUMMON_FORWARD" 6 "RESUME" 5 "PAUSE" 4 "PRIME" 3 "ABORT" 2 "SELF_PARK_REVERSE" 1 "SELF_PARK_FORWARD" 0 "NONE" ;
VAL_ 1016 UI_summonReverseDist 63 "SNA" ;
VAL_ 1016 UI_drivingSide 2 "UNKNOWN" 1 "RIGHT" 0 "LEFT" ;
VAL_ 1016 UI_accFollowDistanceSetting 7 "SNA" 6 "7" 5 "6" 4 "5" 3 "4" 2 "3" 1 "2" 0 "1" ;
VAL_ 1016 UI_followNavRouteEnable 1 "NAV_ROUTE_ON" 0 "NAV_ROUTE_OFF" ;
VAL_ 1016 UI_ulcSpeedConfig 3 "SPEED_BASED_ULC_MAD_MAX" 2 "SPEED_BASED_ULC_AVERAGE" 1 "SPEED_BASED_ULC_MILD" 0 "SPEED_BASED_ULC_DISABLED" ;
VAL_ 1016 UI_ulcBlindSpotConfig 2 "MAD_MAX" 1 "AGGRESSIVE" 0 "STANDARD" ;
VAL_ 1016 UI_smartSummonType 2 "SMART_AUTOPARK" 1 "FIND_ME" 0 "PIN_DROP" ;
VAL_ 1016 UI_source3D 2 "XYZ_PREDICTION" 1 "Z_FROM_PATH_PREDICTION" 0 "Z_FROM_MAP" ;
VAL_ 568 UI_mapSpeedLimitDependency 7 "SNA" 6 "LANE" 5 "SEASON" 4 "TIME" 3 "SNOW" 2 "RAIN" 1 "SCHOOL" 0 "NONE" ;
VAL_ 568 UI_roadClass 6 "CLASS_6_MINOR" 5 "CLASS_5" 4 "CLASS_4" 3 "CLASS_3" 2 "CLASS_2" 1 "CLASS_1_MAJOR" 0 "UNKNOWN_INVALID_SNA" ;
VAL_ 568 UI_mapSpeedUnits 1 "KPH" 0 "MPH" ;
VAL_ 568 UI_mapSpeedLimit 31 "SNA" 30 "UNLIMITED" 29 "LESS_OR_EQ_160" 28 "LESS_OR_EQ_150" 27 "LESS_OR_EQ_140" 26 "LESS_OR_EQ_130" 25 "LESS_OR_EQ_120" 24 "LESS_OR_EQ_115" 23 "LESS_OR_EQ_110" 22 "LESS_OR_EQ_105" 21 "LESS_OR_EQ_100" 20 "LESS_OR_EQ_95" 19 "LESS_OR_EQ_90" 18 "LESS_OR_EQ_85" 17 "LESS_OR_EQ_80" 16 "LESS_OR_EQ_75" 15 "LESS_OR_EQ_70" 14 "LESS_OR_EQ_65" 13 "LESS_OR_EQ_60" 12 "LESS_OR_EQ_55" 11 "LESS_OR_EQ_50" 10 "LESS_OR_EQ_45" 9 "LESS_OR_EQ_40" 8 "LESS_OR_EQ_35" 7 "LESS_OR_EQ_30" 6 "LESS_OR_EQ_25" 5 "LESS_OR_EQ_20" 4 "LESS_OR_EQ_15" 3 "LESS_OR_EQ_10" 2 "LESS_OR_EQ_7" 1 "LESS_OR_EQ_5" 0 "UNKNOWN" ;
VAL_ 568 UI_mapSpeedLimitType 7 "UNKNOWN_SNA" 4 "BUMPS" 3 "DEPENDENT" 2 "ADVISORY" 1 "REGULAR" ;
VAL_ 568 UI_countryCode 1023 "SNA" 0 "UNKNOWN" ;
VAL_ 568 UI_nextBranchDist 31 "SNA" ;
VAL_ 536 UI_roadSign 255 "SNA" 5 "SPLINE_ID_FULL" 4 "SPEED_SPLINE" 3 "SPEED_LIMIT" 2 "TRAFFIC_LIGHT" 1 "STOP_SIGN" 0 "NONE" ;
VAL_ 536 UI_splineLocConfidence 0 "SNA" ;
VAL_ 536 UI_stopSignStopLineDist 1023 "SNA" ;
VAL_ 536 UI_stopSignStopLineConf 0 "SNA" ;
VAL_ 536 UI_trafficLightStopLineDist 1023 "SNA" ;
VAL_ 536 UI_trafficLightStopLineConf 0 "SNA" ;
VAL_ 536 UI_baseMapSpeedLimitMPS 255 "SNA" ;
VAL_ 536 UI_bottomQrtlFleetSpeedMPS 255 "SNA" ;
VAL_ 536 UI_topQrtlFleetSpeedMPS 255 "SNA" ;
VAL_ 536 UI_meanFleetSplineSpeedMPS 255 "SNA" ;
VAL_ 536 UI_medianFleetSpeedMPS 255 "SNA" ;
VAL_ 536 UI_meanFleetSplineAccelMPS2 255 "SNA" ;
VAL_ 536 UI_rampType 4 "INTERCHANGE_EXIT" 3 "INTERCHANGE_ENTRANCE" 2 "EXIT" 1 "ENTRANCE" 0 "NONE_SNA" ;
VAL_ 536 UI_valhallaRamp 2 "ON_RAMP" 1 "NOT_ON_RAMP" 0 "SNA" ;
VAL_ 536 UI_currSplineIdFull 0 "SNA" ;
VAL_ 760 UI_mapSpeedLimitUnits 1 "KPH" 0 "MPH" ;
VAL_ 760 UI_userSpeedOffsetUnits 1 "KPH" 0 "MPH" ;
VAL_ 760 UI_conditionalSpeedLimit 31 "SNA" ;
VAL_ 777 UI_gpsAccuracy 127 "SNA" ;
VAL_ 1011 UI_odometer 16777215 "SNA" ;
VAL_ 987 UI_phoneGpsAccuracy 127 "SNA" ;
VAL_ 820 UI_systemPowerLimit 31 "SNA" ;
VAL_ 820 UI_pedalMap 2 "PERFORMANCE" 1 "SPORT" 0 "CHILL" ;
VAL_ 820 UI_systemTorqueLimit 63 "SNA" ;
VAL_ 820 UI_closureConfirmed 3 "TRUNK" 2 "PROX" 1 "FRUNK" 0 "NONE" ;
VAL_ 820 UI_limitMode 3 "LIMIT_SERVICE" 2 "LIMIT_FACTORY" 1 "LIMIT_VALET" 0 "LIMIT_NORMAL" ;
VAL_ 820 UI_motorOnMode 2 "MOTORONMODE_REAR_ONLY" 1 "MOTORONMODE_FRONT_ONLY" 0 "MOTORONMODE_NORMAL" ;
VAL_ 820 UI_stoppingMode 2 "HOLD" 1 "CREEP" 0 "STANDARD" ;
VAL_ 820 UI_speedLimit 511 "SNA" ;
VAL_ 820 UI_enableSmartShift 2 "ENABLED_P_R_D" 1 "ENABLED_P" 0 "OFF" ;
VAL_ 820 UI_navVehParallelToRdCanContinue 2 "TRUE" 1 "FALSE" 0 "SNA" ;
VAL_ 698 UI_radarTargetDx 255 "NO_OBJECT" ;
VAL_ 698 UI_radarTargetDxEnd 255 "NO_OBJECT" ;
VAL_ 632 UI_roadCurvHealth 3 "DATABASE" 2 "AVAILABLE" 1 "DEGRADED" 0 "UNAVAILABLE" ;
VAL_ 723 UI_solarAzimuthAngle -32768 "SNA" ;
VAL_ 723 UI_solarAzimuthAngleCarRef 255 "SNA" ;
VAL_ 723 UI_isSunUp 3 "SUN_SNA" 1 "SUN_UP" 0 "SUN_DOWN" ;
VAL_ 723 UI_solarElevationAngle 127 "SNA" ;
VAL_ 851 UI_autopilotTrial 3 "ACTIVE" 2 "STOP" 1 "START" 0 "NONE" ;
VAL_ 851 UI_factoryReset 3 "CUSTOMER" 2 "DIAGNOSTIC" 1 "DEVELOPER" 0 "NONE_SNA" ;
VAL_ 851 UI_cellNetworkTechnology 15 "CELL_NETWORK_SNA" 14 "CELL_NETWORK_NGRAN" 13 "CELL_NETWORK_5GSA" 12 "CELL_NETWORK_5GNSA" 11 "CELL_NETWORK_LTE5GCN" 10 "CELL_NETWORK_WCDMA" 9 "CELL_NETWORK_CDMA" 8 "CELL_NETWORK_GSM" 7 "CELL_NETWORK_LTE" 6 "CELL_NETWORK_HSPA" 5 "CELL_NETWORK_HSUPA" 4 "CELL_NETWORK_HSDPA" 3 "CELL_NETWORK_UMTS" 2 "CELL_NETWORK_EDGE" 1 "CELL_NETWORK_GPRS" 0 "CELL_NETWORK_NONE" ;
VAL_ 851 UI_cellSignalBars 7 "SNA" 5 "FIVE" 4 "FOUR" 3 "THREE" 2 "TWO" 1 "ONE" 0 "ZERO" ;
VAL_ 851 UI_trailerModeTelltale 3 "TRAILER_MODE_TELLTALE_RED" 2 "TRAILER_MODE_TELLTALE_YELLOW" 1 "TRAILER_MODE_TELLTALE_BLUE" 0 "TRAILER_MODE_TELLTALE_OFF" ;
VAL_ 991 UI_userActivity 1 "USER_ACTIVE" 0 "USER_IDLE" ;
VAL_ 991 UI_linkState 2 "LINK_STATE_WIFI" 1 "LINK_STATE_CELL" 0 "LINK_STATE_NONE" ;
VAL_ 991 UI_sentryModeState 6 "SNA" 5 "QUIET" 4 "PANIC" 3 "AWARE" 2 "ARMED" 1 "IDLE" 0 "OFF" ;
VAL_ 991 UI_mobileAppConnected 1 "CONNECTED" 0 "NOT_CONNECTED" ;
VAL_ 991 UI_autoshiftDRState 6 "AUTOSHIFT_DR_STATE_BRAKE_GEAR_SHIFT_CONFIRMED_D" 5 "AUTOSHIFT_DR_STATE_BRAKE_GEAR_SHIFT_CONFIRMED_R" 4 "AUTOSHIFT_DR_STATE_BRAKE_STEERING_AND_BRAKE_CONFIRMED" 3 "AUTOSHIFT_DR_STATE_ONLY_STEERING_CONFIRMED" 2 "AUTOSHIFT_DR_STATE_ONLY_BRAKE_CONFIRMED" 1 "AUTOSHIFT_DR_STATE_PROMPT_SHOWING_UNCONFIRMED" 0 "AUTOSHIFT_DR_STATE_INACTIVE" ;
VAL_ 991 UI_wifiBtModuleType 4 "ELEKTRA" 3 "TCU4G" 2 "BCM4359" 1 "QCA6595" 0 "UNKNOWN" ;
VAL_ 991 UI_sohHealthStatus 3 "OK" 2 "REDUCED" 1 "NO_INTERNET" 0 "UNKNOWN" ;
VAL_ 991 UI_selfParkState 255 "SNA" 52 "SELF_PARK_USER_PAUSED" 51 "SELF_PARK_REMOTE_PRE_ABORT" 50 "SELF_PARK_RESUME" 49 "SELF_PARK_PAUSE" 48 "SELF_PARK_DV_MISMATCH" 47 "SELF_PARK_DI_PANIC" 46 "SELF_PARK_POST_ACTIVE_FAILURE" 45 "SELF_PARK_POST_ACTIVE_SUCCESS" 44 "SELF_PARK_CANCEL_AUTO_SUMMON" 43 "SELF_PARK_REMOTE_ABORT" 42 "SELF_PARK_OBSTACLE_NOT_CLEARED" 41 "SELF_PARK_OBSTACLE_CLEARED" 40 "SELF_PARK_OPEN_GATE" 39 "SELF_PARK_ACTIVE" 38 "SELF_PARK_STARTED_REVERSE" 37 "SELF_PARK_STARTED_FORWARD" 36 "SELF_PARK_NOT_STARTED_TIMEOUT" 35 "SELF_PARK_PRIMED" 34 "SELF_PARK_PREPRIMED" 33 "SELF_PARK_TURN_ON_DRIVE_RAIL" 32 "SELF_PARK_DETECT_KEY_FOB" 31 "SELF_PARK_WAKE_UP_BUSES" 30 "SELF_PARK_CONNECTING_BLUETOOTH" 29 "SELF_PARK_UNAVAILABLE_CAR_WASH_MODE" 28 "SELF_PARK_UNAVAILABLE_CAR_ALARM" 27 "SELF_PARK_UNAVAILABLE_CRASH_STATE" 26 "SELF_PARK_UNAVAILABLE_DRAG_STRIP_MODE" 25 "SELF_PARK_UNAVAILABLE_TRACK_MODE" 24 "SELF_PARK_UNAVAILABLE_SERVICE_MODE" 23 "SELF_PARK_UNAVAILABLE_DOG_MODE" 22 "SELF_PARK_UNAVAILABLE_GAME_MODE" 21 "SELF_PARK_UNAVAILABLE_BLUETOOTH_CONNECT_TIMEOUT" 20 "SELF_PARK_UNAVAILABLE_WAKEUP_TIMEOUT" 19 "SELF_PARK_UNAVAILABLE_NO_BLUETOOTH_DEVICES_PAIRED" 18 "SELF_PARK_UNAVAILABLE_BRAKE_PRESSED" 17 "SELF_PARK_UNAVAILABLE_ROAD_GRADE" 16 "SELF_PARK_UNAVAILABLE_TRAILER_MODE" 15 "SELF_PARK_UNAVAILABLE_KEY_FOB_BATTERY_LOW" 14 "SELF_PARK_UNAVAILABLE_KEY_FOB_NOT_DETECTED" 13 "SELF_PARK_UNAVAILABLE_PARK_SENSOR_ISSUE" 12 "SELF_PARK_UNAVAILABLE_AUTOSTEER_NOT_ENABLED" 11 "SELF_PARK_UNAVAILABLE_LV_BUS_SUPPORT_ISSUE" 10 "SELF_PARK_UNAVAILABLE_ON_PUBLIC_ROAD" 9 "SELF_PARK_UNAVAILABLE_PARKED_TOO_LONG" 8 "SELF_PARK_UNAVAILABLE_DOOR_OPEN" 7 "SELF_PARK_UNAVAILABLE_TRUNK_OPEN" 6 "SELF_PARK_UNAVAILABLE_FRUNK_OPEN" 5 "SELF_PARK_UNAVAILABLE_PLUGGED_IN" 4 "SELF_PARK_UNAVAILABLE_NOT_PARKED" 3 "SELF_PARK_UNAVAILABLE" 2 "SELF_PARK_IDLE" 1 "SELF_PARK_DRIVING" 0 "SELF_PARK_DISABLED" ;
VAL_ 991 UI_summonDeviceIndex 3 "UNKNOWN" 2 "DEVICE_2" 1 "DEVICE_1" 0 "DEVICE_0" ;
VAL_ 856 UI_TPMSMode 2 "PERFORMANCE_MODE" 1 "NORMAL_MODE" 0 "UNUSED_MODE" ;
VAL_ 856 UI_TPMSLearnIDMode 4 "AUTO_LOCATION_ACTIVE_AFTER_PWR" 3 "AUTO_LEARN_ACTIVE_AFTER_PWR" 2 "AUTO_LOCATION_ACTIVE_BY_MANUAL" 1 "AUTO_LEARN_ACTIVE_BY_MANUAL" 0 "NO_ID_LEARN_FUNCTION" ;
VAL_ 856 UI_sizeOfWheelSelect 2 "19_INCH_WHEEL" 1 "18_INCH_WHEEL" 0 "UNUSED" ;
VAL_ 852 UI_centerDisplaySM 4 "DOWN" 3 "TIMING_OUT" 2 "STALLING" 1 "UP" 0 "START" ;
VAL_ 852 UI_autonomyCenterDispStatus 2 "UNAVAILABLE" 1 "AVAILABLE" 0 "SNA" ;
VAL_ 852 UI_autonomyRearDispStatus 2 "UNAVAILABLE" 1 "AVAILABLE" 0 "SNA" ;
VAL_ 852 UI_autonomyConnectivityStatus 2 "OFFLINE" 1 "ONLINE" 0 "SNA" ;
VAL_ 852 UI_autonomyQtCarStatus 2 "UNAVAILABLE" 1 "AVAILABLE" 0 "SNA" ;
VAL_ 852 UI_autonomyQtCarRearStatus 2 "UNAVAILABLE" 1 "AVAILABLE" 0 "SNA" ;
VAL_ 852 UI_autonomyDASServerStatus 2 "UNAVAILABLE" 1 "AVAILABLE" 0 "SNA" ;
VAL_ 852 UI_rearDisplaySM 4 "DOWN" 3 "TIMING_OUT" 2 "STALLING" 1 "UP" 0 "START" ;
VAL_ 1827 UI_ussSensorIdX 5 "FRONT_SIDE" 4 "FRONT_CORNER" 3 "FRONT_INNER" 2 "REAR_SIDE" 1 "REAR_CORNER" 0 "REAR_INNER" ;
VAL_ 1829 UI_ussSensorIdY 5 "FRONT_SIDE" 4 "FRONT_CORNER" 3 "FRONT_INNER" 2 "REAR_SIDE" 1 "REAR_CORNER" 0 "REAR_INNER" ;
VAL_ 947 UI_lightSwitch 4 "LIGHT_SWITCH_SNA" 3 "LIGHT_SWITCH_OFF" 2 "LIGHT_SWITCH_PARKING" 1 "LIGHT_SWITCH_ON" 0 "LIGHT_SWITCH_AUTO" ;
VAL_ 947 UI_summonState 3 "ACTIVE" 2 "PRE_PRIMED" 1 "IDLE" 0 "SNA" ;
VAL_ 947 UI_autopilotPowerStateRequest 2 "AUTOPILOT_SUSPEND" 1 "AUTOPILOT_SENTRY" 0 "AUTOPILOT_NOMINAL" ;
VAL_ 947 UI_shorted12VCellTestMode 2 "ACTIVE" 1 "SHADOW" 0 "DISABLED" ;
VAL_ 947 UI_frontLeftSeatFanReq 3 "FAN_REQUEST_LEVEL3" 2 "FAN_REQUEST_LEVEL2" 1 "FAN_REQUEST_LEVEL1" 0 "FAN_REQUEST_OFF" ;
VAL_ 947 UI_frontRightSeatFanReq 3 "FAN_REQUEST_LEVEL3" 2 "FAN_REQUEST_LEVEL2" 1 "FAN_REQUEST_LEVEL1" 0 "FAN_REQUEST_OFF" ;
VAL_ 947 UI_3RLeftSeatHeatReq 3 "HEATER_REQUEST_LEVEL3" 2 "HEATER_REQUEST_LEVEL2" 1 "HEATER_REQUEST_LEVEL1" 0 "HEATER_REQUEST_OFF" ;
VAL_ 947 UI_3RRightSeatHeatReq 3 "HEATER_REQUEST_LEVEL3" 2 "HEATER_REQUEST_LEVEL2" 1 "HEATER_REQUEST_LEVEL1" 0 "HEATER_REQUEST_OFF" ;
VAL_ 947 UI_dcr12VThreshold 12 "15_MILLIOHMS" 11 "16_MILLIOHMS" 10 "17_MILLIOHMS" 9 "18_MILLIOHMS" 8 "19_MILLIOHMS" 7 "20_MILLIOHMS" 6 "22_MILLIOHMS" 5 "24_MILLIOHMS" 4 "27_MILLIOHMS" 3 "30_MILLIOHMS" 2 "35_MILLIOHMS" 1 "40_MILLIOHMS" 0 "OFF" ;
VAL_ 947 UI_tireSeason 1 "WINTER" 0 "NON_WINTER" ;
VAL_ 947 UI_saveTireConfigReq 1 "TRUE" 0 "FALSE" ;
VAL_ 644 UI_factoryMode 1 "ENABLED" 0 "DISABLED" ;
VAL_ 644 UI_transportMode 1 "TRANSPORT_MODE_ENABLED" 0 "TRANSPORT_MODE_DISABLED" ;
VAL_ 644 UI_showroomMode 1 "SHOWROOM_MODE_ENABLED" 0 "SHOWROOM_MODE_DISABLED" ;
VAL_ 644 UI_serviceMode 1 "SERVICE_MODE_ENABLED" 0 "SERVICE_MODE_DISABLED" ;
VAL_ 644 UI_diagnosticsAllowed 1 "ALLOWED" 0 "NOT_ALLOWED" ;
VAL_ 644 UI_serviceModePlus 1 "SERVICE_MODE_PLUS_ENABLED" 0 "SERVICE_MODE_PLUS_DISABLED" ;
VAL_ 644 UI_signedCmdHardLocked 1 "ENABLED" 0 "DISABLED" ;
VAL_ 644 UI_signedCmdServiceMode 1 "ENABLED" 0 "DISABLED" ;
VAL_ 644 UI_closureEasterEggStatus 3 "PLAYING" 2 "PRIMED" 1 "PRIMED_REMOTE" 0 "IDLE" ;
VAL_ 644 UI_lightShowType 5 "LIGHT_SHOW_TYPE_STANDARD_CNY24" 4 "LIGHT_SHOW_TYPE_STANDARD_THE_ARRIVAL" 3 "LIGHT_SHOW_TYPE_STANDARD_CNY23" 2 "LIGHT_SHOW_TYPE_STANDARD_AULD_LANG_SYNE" 1 "LIGHT_SHOW_TYPE_STANDARD_CAROL_OF_THE_BELLS" 0 "LIGHT_SHOW_TYPE_CUSTOM_USB" ;
VAL_ 644 UI_upkeepMode 1 "UI_UPKEEPMODE_ENABLED" 0 "UI_UPKEEPMODE_DISABLED" ;
VAL_ 1569 UI_weatherSvcTimeSinceLast 127 "SNA" ;
VAL_ 1569 UI_weatherSvcWindDir 255 "SNA" 240 "MAX" 0 "MIN" ;
VAL_ 1569 UI_weatherSvcTemperature 255 "SNA" 250 "MAX" 0 "MIN" ;
VAL_ 1569 UI_weatherSvcHumidity 63 "SNA" 62 "MAX" 0 "MIN" ;
VAL_ 1569 UI_weatherSvcDewPoint 255 "SNA" 250 "MAX" 0 "MIN" ;
VAL_ 1569 UI_weatherSvcCloudCover 63 "SNA" 62 "MAX" 0 "MIN" ;
VAL_ 1569 UI_weatherSvcPrecipProb 63 "SNA" 62 "MAX" 0 "MIN" ;
VAL_ 1569 UI_weatherSvcWindSpeed 63 "SNA" 60 "MAX" 0 "MIN" ;
